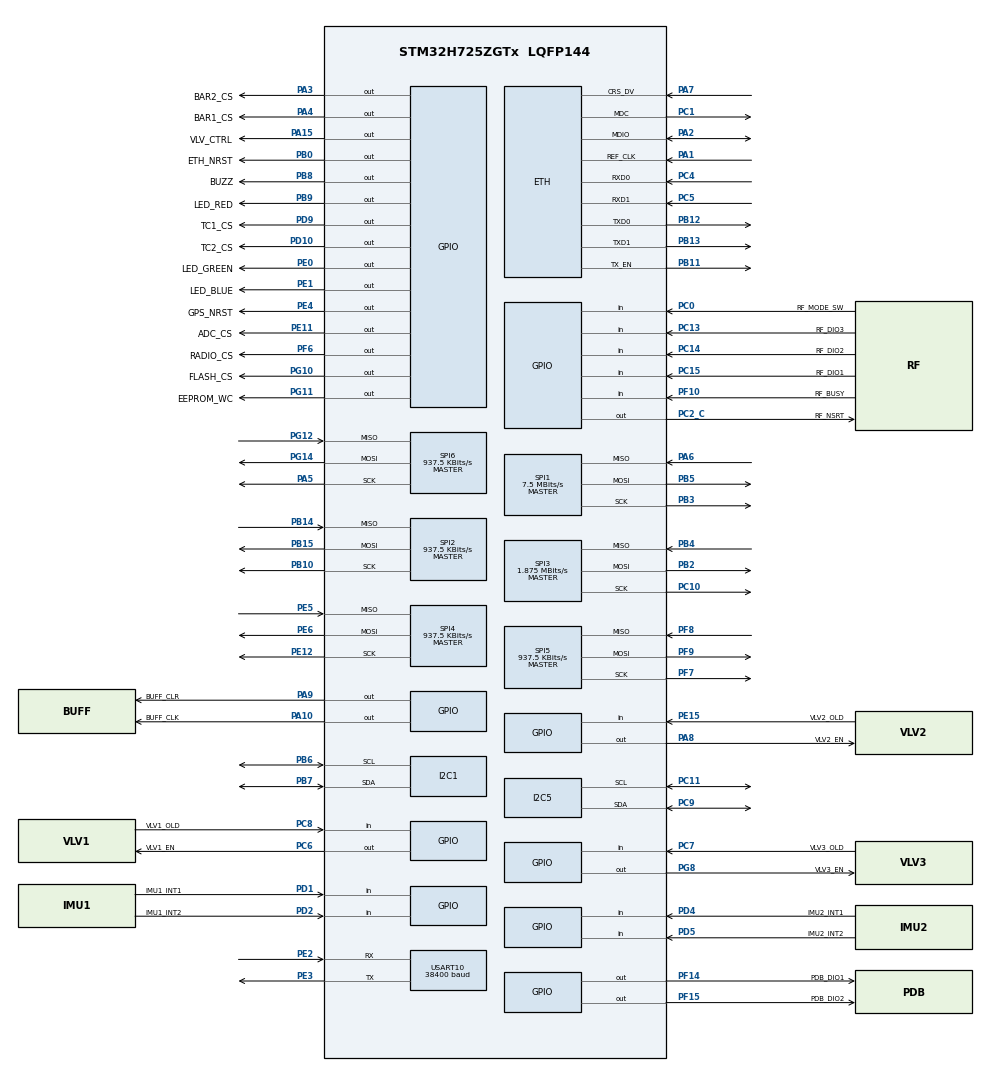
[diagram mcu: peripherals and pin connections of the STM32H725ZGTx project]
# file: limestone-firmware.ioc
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CORTEX_M7.AccessPermission-Cortex_Memory_Protection_Unit_Region0_Settings=MPU_REGION_NO_ACCESS
CORTEX_M7.AccessPermission-Cortex_Memory_Protection_Unit_Region1_Settings=MPU_REGION_FULL_ACCESS
CORTEX_M7.AccessPermission-Cortex_Memory_Protection_Unit_Region2_Settings=MPU_REGION_FULL_ACCESS
CORTEX_M7.AccessPermission_S-Cortex_Memory_Protection_Unit_Region1_Settings_S=MPU_REGION_FULL_ACCESS
CORTEX_M7.AccessPermission_S-Cortex_Memory_Protection_Unit_Region2_Settings_S=MPU_REGION_FULL_ACCESS
CORTEX_M7.AccessPermission_Spec=MPU_REGION_NO_ACCESS
CORTEX_M7.BaseAddress-Cortex_Memory_Protection_Unit_Region0_Settings=0x00000000
CORTEX_M7.BaseAddress-Cortex_Memory_Protection_Unit_Region1_Settings=0x30000200
CORTEX_M7.BaseAddress-Cortex_Memory_Protection_Unit_Region2_Settings=0x30000000
CORTEX_M7.BaseAddress_S-Cortex_Memory_Protection_Unit_Region1_Settings_S=0x30000200
CORTEX_M7.BaseAddress_S-Cortex_Memory_Protection_Unit_Region2_Settings_S=0x30000000
CORTEX_M7.CPU_DCache=Enabled
CORTEX_M7.CPU_ICache=Enabled
CORTEX_M7.DisableExec-Cortex_Memory_Protection_Unit_Region0_Settings=MPU_INSTRUCTION_ACCESS_DISABLE
CORTEX_M7.DisableExec-Cortex_Memory_Protection_Unit_Region1_Settings=MPU_INSTRUCTION_ACCESS_DISABLE
CORTEX_M7.DisableExec-Cortex_Memory_Protection_Unit_Region2_Settings=MPU_INSTRUCTION_ACCESS_DISABLE
CORTEX_M7.DisableExec_S-Cortex_Memory_Protection_Unit_Region1_Settings_S=MPU_INSTRUCTION_ACCESS_DISABLE
CORTEX_M7.DisableExec_S-Cortex_Memory_Protection_Unit_Region2_Settings_S=MPU_INSTRUCTION_ACCESS_DISABLE
CORTEX_M7.Enable-Cortex_Memory_Protection_Unit_Region0_Settings=MPU_REGION_ENABLE
CORTEX_M7.Enable-Cortex_Memory_Protection_Unit_Region1_Settings=MPU_REGION_ENABLE
CORTEX_M7.Enable-Cortex_Memory_Protection_Unit_Region2_Settings=MPU_REGION_ENABLE
CORTEX_M7.Enable_S-Cortex_Memory_Protection_Unit_Region1_Settings_S=MPU_REGION_ENABLE
CORTEX_M7.Enable_S-Cortex_Memory_Protection_Unit_Region2_Settings_S=MPU_REGION_ENABLE
CORTEX_M7.IsBufferable-Cortex_Memory_Protection_Unit_Region1_Settings=MPU_ACCESS_NOT_BUFFERABLE
CORTEX_M7.IsBufferable-Cortex_Memory_Protection_Unit_Region2_Settings=MPU_ACCESS_BUFFERABLE
CORTEX_M7.IsBufferable_S-Cortex_Memory_Protection_Unit_Region2_Settings_S=MPU_ACCESS_BUFFERABLE
CORTEX_M7.IsCacheable-Cortex_Memory_Protection_Unit_Region1_Settings=MPU_ACCESS_NOT_CACHEABLE
CORTEX_M7.IsShareable-Cortex_Memory_Protection_Unit_Region0_Settings=MPU_ACCESS_SHAREABLE
CORTEX_M7.IsShareable-Cortex_Memory_Protection_Unit_Region2_Settings=MPU_ACCESS_SHAREABLE
CORTEX_M7.IsShareable_S-Cortex_Memory_Protection_Unit_Region1_Settings_S=MPU_ACCESS_NOT_SHAREABLE
CORTEX_M7.IsShareable_S-Cortex_Memory_Protection_Unit_Region2_Settings_S=MPU_ACCESS_SHAREABLE
CORTEX_M7.MPU_Control=MPU_PRIVILEGED_DEFAULT
CORTEX_M7.Size-Cortex_Memory_Protection_Unit_Region0_Settings=MPU_REGION_SIZE_4GB
CORTEX_M7.Size-Cortex_Memory_Protection_Unit_Region1_Settings=MPU_REGION_SIZE_128KB
CORTEX_M7.Size-Cortex_Memory_Protection_Unit_Region2_Settings=MPU_REGION_SIZE_512B
CORTEX_M7.Size_S-Cortex_Memory_Protection_Unit_Region1_Settings_S=MPU_REGION_SIZE_32KB
CORTEX_M7.Size_S-Cortex_Memory_Protection_Unit_Region2_Settings_S=MPU_REGION_SIZE_512B
CORTEX_M7.SubRegionDisable-Cortex_Memory_Protection_Unit_Region0_Settings=0x87
CORTEX_M7.SubRegionDisable_S-Cortex_Memory_Protection_Unit_Region1_Settings_S=0x0
CORTEX_M7.TypeExtField-Cortex_Memory_Protection_Unit_Region1_Settings=MPU_TEX_LEVEL1
CORTEX_M7.TypeExtField_S-Cortex_Memory_Protection_Unit_Region1_Settings_S=MPU_TEX_LEVEL1
CORTEX_M7.default_mode_Activation=1
CRC.InputDataInversionMode=CRC_INPUTDATA_INVERSION_BYTE
CRC.OutputDataInversionMode=CRC_OUTPUTDATA_INVERSION_ENABLE
ETH.ETH_RX_DESC_CNT=8
ETH.ETH_TX_DESC_CNT=8
ETH.MediaInterface=HAL_ETH_RMII_MODE
ETH.RxBuffLen=1536
ETH.RxBufferAddress=0x30000200
ETH.TxDescAddress=0x30000100
FREERTOS.Tasks01=startTask,24,1024,StartAndMonitor,Default,NULL,Dynamic,NULL,NULL
FREERTOS.configCHECK_FOR_STACK_OVERFLOW=2
FREERTOS.configGENERATE_RUN_TIME_STATS=1
FREERTOS.configTOTAL_HEAP_SIZE=114688
FREERTOS.configUSE_NEWLIB_REENTRANT=1
I2C1.Timing=0x307075B1
I2C5.Timing=0x307075B1
LWIP.BSP.number=1
LWIP.DEFAULT_ACCEPTMBOX_SIZE=32
LWIP.DEFAULT_TCP_RECVMBOX_SIZE=64
LWIP.DEFAULT_UDP_RECVMBOX_SIZE=64
LWIP.ETHARP_DEBUG=LWIP_DBG_OFF
LWIP.ETH_RX_BUFFER_CNT=12
LWIP.IP_ADDRESS=000.000.000.000
LWIP.LWIP_DBG_MIN_LEVEL=LWIP_DBG_LEVEL_WARNING
LWIP.LWIP_DBG_TYPES_ON=LWIP_DBG_OFF
LWIP.LWIP_DHCP=0
LWIP.LWIP_NETCONN_SEM_PER_THREAD=0
LWIP.LWIP_PERF=1
LWIP.LWIP_RAM_HEAP_POINTER=0x30000200
LWIP.LWIP_SNTP=1
LWIP.LWIP_SO_RCVTIMEO=1
LWIP.LWIP_SO_SNDTIMEO=1
LWIP.LWIP_STATS=1
LWIP.LWIP_TCPIP_TIMEOUT=1
LWIP.LWIP_TCP_KEEPALIVE=1
LWIP.LWIP_TFTP=1
LWIP.MEMP_NUM_API_MSG=10
LWIP.MEMP_NUM_NETBUF=64
LWIP.MEMP_NUM_NETCONN=10
LWIP.MEMP_NUM_NETDB=4
LWIP.MEMP_NUM_SYS_TIMEOUT=16
LWIP.MEMP_NUM_TCPIP_MSG_INPKT=64
LWIP.MEMP_NUM_TCP_PCB=9
LWIP.MEMP_NUM_TCP_SEG=32
LWIP.MEMP_NUM_UDP_PCB=6
LWIP.MEM_SIZE=32232
LWIP.NETIF_DEBUG=LWIP_DBG_OFF
LWIP.NETMASK_ADDRESS=255.255.255.000
LWIP.PBUF_DEBUG=LWIP_DBG_OFF
LWIP.PBUF_POOL_BUFSIZE=1536
LWIP.PBUF_POOL_SIZE=64
LWIP.SO_REUSE=1
LWIP.SYS_DEBUG=LWIP_DBG_OFF
LWIP.TCPIP_MBOX_SIZE=64
LWIP.TCPIP_THREAD_STACKSIZE=6400
LWIP.TCP_CWND_DEBUG=LWIP_DBG_OFF
LWIP.TCP_DEBUG=LWIP_DBG_OFF
LWIP.TCP_FR_DEBUG=LWIP_DBG_OFF
LWIP.TCP_INPUT_DEBUG=LWIP_DBG_OFF
LWIP.TCP_MSS=1460
LWIP.TCP_OUTPUT_DEBUG=LWIP_DBG_OFF
LWIP.TCP_QLEN_DEBUG=LWIP_DBG_OFF
LWIP.TCP_RST_DEBUG=LWIP_DBG_OFF
LWIP.TCP_RTO_DEBUG=LWIP_DBG_OFF
LWIP.TCP_SND_BUF=5840
LWIP.TCP_SND_QUEUELEN=16
LWIP.TCP_WND_DEBUG=LWIP_DBG_OFF
LWIP.TIMERS_DEBUG=LWIP_DBG_OFF
LWIP.Version=v2.1.2_Cube
LWIP0.BSP.STBoard=false
LWIP0.BSP.api=BSP_COMPONENT_DRIVER
LWIP0.BSP.component=LAN8742
LWIP0.BSP.instance=LAN8742
LWIP0.BSP.name=Driver_PHY
LWIP0.BSP.semaphore=S_LAN8742
LWIP0.BSP.solution=LAN8742
Mcu.Family=STM32H7
Mcu.Name=STM32H725ZGTx
Mcu.Package=LQFP144
NVIC.ETH_IRQn=true\:5\:0\:true\:false\:true\:true\:true\:true\:true
NVIC.PriorityGroup=NVIC_PRIORITYGROUP_4
NVIC.TIM6_DAC_IRQn=true\:15\:0\:false\:false\:true\:false\:false\:true\:true
NVIC.TIM8_TRG_COM_TIM14_IRQn=true\:5\:0\:false\:false\:true\:true\:true\:true\:true
NVIC.TimeBase=TIM6_DAC_IRQn
NVIC.TimeBaseIP=TIM6
NVIC.USART10_IRQn=true\:5\:0\:false\:false\:true\:true\:true\:true\:true
PA1.GPIO_Speed=GPIO_SPEED_FREQ_VERY_HIGH
PA1.Mode=RMII
PA1.Signal=ETH_REF_CLK
PA10.GPIO_Label=BUFF_CLK
PA10.GPIO_Speed=GPIO_SPEED_FREQ_VERY_HIGH
PA10.Signal=GPIO_Output
PA13(JTMS/SWDIO).Mode=Serial_Wire
PA13(JTMS/SWDIO).Signal=DEBUG_JTMS-SWDIO
PA14(JTCK/SWCLK).Mode=Serial_Wire
PA14(JTCK/SWCLK).Signal=DEBUG_JTCK-SWCLK
PA15(JTDI).GPIO_Label=VLV_CTRL
PA15(JTDI).GPIO_PuPd=GPIO_NOPULL
PA15(JTDI).GPIO_Speed=GPIO_SPEED_FREQ_VERY_HIGH
PA15(JTDI).Signal=GPIO_Output
PA2.GPIO_Speed=GPIO_SPEED_FREQ_VERY_HIGH
PA2.Mode=RMII
PA2.Signal=ETH_MDIO
PA3.GPIO_Label=BAR2_CS
PA3.PinState=GPIO_PIN_SET
PA3.Signal=GPIO_Output
PA4.GPIO_Label=BAR1_CS
PA4.PinState=GPIO_PIN_SET
PA4.Signal=GPIO_Output
PA5.GPIO_Speed=GPIO_SPEED_FREQ_LOW
PA5.Mode=Full_Duplex_Master
PA5.Signal=SPI6_SCK
PA6.GPIO_Speed=GPIO_SPEED_FREQ_MEDIUM
PA6.Mode=Full_Duplex_Master
PA6.Signal=SPI1_MISO
PA7.GPIO_Speed=GPIO_SPEED_FREQ_VERY_HIGH
PA7.Mode=RMII
PA7.Signal=ETH_CRS_DV
PA8.GPIO_Label=VLV2_EN
PA8.Signal=GPIO_Output
PA9.GPIO_Label=BUFF_CLR
PA9.GPIO_Speed=GPIO_SPEED_FREQ_VERY_HIGH
PA9.Signal=GPIO_Output
PB0.GPIO_Label=ETH_NRST
PB0.PinState=GPIO_PIN_SET
PB0.Signal=GPIO_Output
PB10.GPIO_Speed=GPIO_SPEED_FREQ_LOW
PB10.Mode=Full_Duplex_Master
PB10.Signal=SPI2_SCK
PB11.GPIO_Speed=GPIO_SPEED_FREQ_VERY_HIGH
PB11.Mode=RMII
PB11.Signal=ETH_TX_EN
PB12.GPIO_Speed=GPIO_SPEED_FREQ_VERY_HIGH
PB12.Mode=RMII
PB12.Signal=ETH_TXD0
PB13.GPIO_Speed=GPIO_SPEED_FREQ_VERY_HIGH
PB13.Mode=RMII
PB13.Signal=ETH_TXD1
PB14.GPIO_Speed=GPIO_SPEED_FREQ_LOW
PB14.Mode=Full_Duplex_Master
PB14.Signal=SPI2_MISO
PB15.GPIO_Speed=GPIO_SPEED_FREQ_LOW
PB15.Mode=Full_Duplex_Master
PB15.Signal=SPI2_MOSI
PB2.GPIO_Speed=GPIO_SPEED_FREQ_LOW
PB2.Mode=Full_Duplex_Master
PB2.Signal=SPI3_MOSI
PB3(JTDO/TRACESWO).GPIO_Speed=GPIO_SPEED_FREQ_MEDIUM
PB3(JTDO/TRACESWO).Mode=Full_Duplex_Master
PB3(JTDO/TRACESWO).Signal=SPI1_SCK
PB4(NJTRST).GPIO_Speed=GPIO_SPEED_FREQ_LOW
PB4(NJTRST).Mode=Full_Duplex_Master
PB4(NJTRST).Signal=SPI3_MISO
PB5.GPIO_Speed=GPIO_SPEED_FREQ_MEDIUM
PB5.Mode=Full_Duplex_Master
PB5.Signal=SPI1_MOSI
PB6.Mode=I2C
PB6.Signal=I2C1_SCL
PB7.Mode=I2C
PB7.Signal=I2C1_SDA
PB8.GPIO_Label=BUZZ
PB8.Signal=GPIO_Output
PB9.GPIO_Label=LED_RED
PB9.Signal=GPIO_Output
PC0.GPIO_Label=RF_MODE_SW
PC0.Signal=GPIO_Input
PC1.GPIO_Speed=GPIO_SPEED_FREQ_VERY_HIGH
PC1.Mode=RMII
PC1.Signal=ETH_MDC
PC10.GPIO_Speed=GPIO_SPEED_FREQ_LOW
PC10.Mode=Full_Duplex_Master
PC10.Signal=SPI3_SCK
PC11.Mode=I2C
PC11.Signal=I2C5_SCL
PC13.GPIO_Label=RF_DIO3
PC13.Signal=GPIO_Input
PC14-OSC32_IN.GPIO_Label=RF_DIO2
PC14-OSC32_IN.Signal=GPIO_Input
PC15-OSC32_OUT.GPIO_Label=RF_DIO1
PC15-OSC32_OUT.Signal=GPIO_Input
PC2_C.GPIO_Label=RF_NSRT
PC2_C.PinState=GPIO_PIN_SET
PC2_C.Signal=GPIO_Output
PC4.GPIO_Speed=GPIO_SPEED_FREQ_VERY_HIGH
PC4.Mode=RMII
PC4.Signal=ETH_RXD0
PC5.GPIO_Speed=GPIO_SPEED_FREQ_VERY_HIGH
PC5.Mode=RMII
PC5.Signal=ETH_RXD1
PC6.GPIO_Label=VLV1_EN
PC6.Signal=GPIO_Output
PC7.GPIO_Label=VLV3_OLD
PC7.Signal=GPIO_Input
PC8.GPIO_Label=VLV1_OLD
PC8.Signal=GPIO_Input
PC9.Mode=I2C
PC9.Signal=I2C5_SDA
PD1.GPIO_Label=IMU1_INT1
PD1.Signal=GPIO_Input
PD10.GPIO_Label=TC2_CS
PD10.PinState=GPIO_PIN_SET
PD10.Signal=GPIO_Output
PD2.GPIO_Label=IMU1_INT2
PD2.Signal=GPIO_Input
PD4.GPIO_Label=IMU2_INT1
PD4.Signal=GPIO_Input
PD5.GPIO_Label=IMU2_INT2
PD5.Signal=GPIO_Input
PD9.GPIO_Label=TC1_CS
PD9.PinState=GPIO_PIN_SET
PD9.Signal=GPIO_Output
PE0.GPIO_Label=LED_GREEN
PE0.Signal=GPIO_Output
PE1.GPIO_Label=LED_BLUE
PE1.Signal=GPIO_Output
PE11.GPIO_Label=ADC_CS
PE11.PinState=GPIO_PIN_SET
PE11.Signal=GPIO_Output
PE12.Mode=Full_Duplex_Master
PE12.Signal=SPI4_SCK
PE15.GPIO_Label=VLV2_OLD
PE15.Signal=GPIO_Input
PE2.Mode=Asynchronous
PE2.Signal=USART10_RX
PE3.Mode=Asynchronous
PE3.Signal=USART10_TX
PE4.GPIO_Label=GPS_NRST
PE4.PinState=GPIO_PIN_SET
PE4.Signal=GPIO_Output
PE5.GPIO_Speed=GPIO_SPEED_FREQ_LOW
PE5.Mode=Full_Duplex_Master
PE5.Signal=SPI4_MISO
PE6.GPIO_Speed=GPIO_SPEED_FREQ_LOW
PE6.Mode=Full_Duplex_Master
PE6.Signal=SPI4_MOSI
PF10.GPIO_Label=RF_BUSY
PF10.Signal=GPIO_Input
PF14.GPIO_Label=PDB_DIO1
PF14.Signal=GPIO_Output
PF15.GPIO_Label=PDB_DIO2
PF15.Signal=GPIO_Output
PF6.GPIO_Label=RADIO_CS
PF6.PinState=GPIO_PIN_SET
PF6.Signal=GPIO_Output
PF7.Mode=Full_Duplex_Master
PF7.Signal=SPI5_SCK
PF8.Mode=Full_Duplex_Master
PF8.Signal=SPI5_MISO
PF9.Mode=Full_Duplex_Master
PF9.Signal=SPI5_MOSI
PG10.GPIO_Label=FLASH_CS
PG10.PinState=GPIO_PIN_SET
PG10.Signal=GPIO_Output
PG11.GPIO_Label=EEPROM_WC
PG11.PinState=GPIO_PIN_SET
PG11.Signal=GPIO_Output
PG12.Mode=Full_Duplex_Master
PG12.Signal=SPI6_MISO
PG14.Mode=Full_Duplex_Master
PG14.Signal=SPI6_MOSI
PG8.GPIO_Label=VLV3_EN
PG8.Signal=GPIO_Output
PH0-OSC_IN.Mode=HSE-External-Oscillator
PH0-OSC_IN.Signal=RCC_OSC_IN
PH1-OSC_OUT.Mode=HSE-External-Oscillator
PH1-OSC_OUT.Signal=RCC_OSC_OUT
ProjectManager.HeapSize=0x200
ProjectManager.StackSize=0x400
ProjectManager.TargetToolchain=STM32CubeIDE
RCC.ADCFreq_Value=387000000
RCC.APB1Freq_Value=120000000
RCC.APB2Freq_Value=120000000
RCC.APB3Freq_Value=120000000
RCC.APB4Freq_Value=120000000
RCC.CortexFreq_Value=480000000
RCC.D1PPRE=RCC_APB3_DIV2
RCC.D2PPRE1=RCC_APB1_DIV2
RCC.D2PPRE2=RCC_APB2_DIV2
RCC.D3PPRE=RCC_APB4_DIV2
RCC.DIVM1=3
RCC.DIVM2=8
RCC.DIVM3=8
RCC.DIVN1=30
RCC.DIVP1=1
RCC.HCLKFreq_Value=240000000
RCC.HPRE=RCC_HCLK_DIV2
RCC.HSE_VALUE=48000000
RCC.PLLFRACN=0
RCC.PLLSourceVirtual=RCC_PLLSOURCE_HSE
RCC.RCC_RTC_Clock_Source_FROM_HSE=RCC_RTCCLKSOURCE_HSE_DIV60
RCC.RTCClockSelection=RCC_RTCCLKSOURCE_HSE_DIV60
RCC.SYSCLKFreq_VALUE=480000000
RCC.SYSCLKSource=RCC_SYSCLKSOURCE_PLLCLK
RCC.SupplySource=PWR_LDO_SUPPLY
RCC.USBFreq_Value=240000000
RTC.Format=RTC_FORMAT_BIN
RTC.SynchPrediv=6249
SPI1.BaudRatePrescaler=SPI_BAUDRATEPRESCALER_32
SPI1.CalculateBaudRate=7.5 MBits/s
SPI1.DataSize=SPI_DATASIZE_8BIT
SPI1.Direction=SPI_DIRECTION_2LINES
SPI1.Mode=SPI_MODE_MASTER
SPI1.VirtualType=VM_MASTER
SPI2.BaudRatePrescaler=SPI_BAUDRATEPRESCALER_256
SPI2.CLKPhase=SPI_PHASE_2EDGE
SPI2.CalculateBaudRate=937.5 KBits/s
SPI2.DataSize=SPI_DATASIZE_8BIT
SPI2.Direction=SPI_DIRECTION_2LINES
SPI2.Mode=SPI_MODE_MASTER
SPI2.VirtualType=VM_MASTER
SPI3.BaudRatePrescaler=SPI_BAUDRATEPRESCALER_128
SPI3.CalculateBaudRate=1.875 MBits/s
SPI3.DataSize=SPI_DATASIZE_8BIT
SPI3.Direction=SPI_DIRECTION_2LINES
SPI3.Mode=SPI_MODE_MASTER
SPI3.VirtualType=VM_MASTER
SPI4.BaudRatePrescaler=SPI_BAUDRATEPRESCALER_128
SPI4.CLKPhase=SPI_PHASE_2EDGE
SPI4.CLKPolarity=SPI_POLARITY_HIGH
SPI4.CalculateBaudRate=937.5 KBits/s
SPI4.DataSize=SPI_DATASIZE_8BIT
SPI4.Direction=SPI_DIRECTION_2LINES
SPI4.Mode=SPI_MODE_MASTER
SPI4.VirtualType=VM_MASTER
SPI5.BaudRatePrescaler=SPI_BAUDRATEPRESCALER_128
SPI5.CalculateBaudRate=937.5 KBits/s
SPI5.DataSize=SPI_DATASIZE_8BIT
SPI5.Direction=SPI_DIRECTION_2LINES
SPI5.Mode=SPI_MODE_MASTER
SPI5.VirtualType=VM_MASTER
SPI6.BaudRatePrescaler=SPI_BAUDRATEPRESCALER_128
SPI6.CalculateBaudRate=937.5 KBits/s
SPI6.DataSize=SPI_DATASIZE_8BIT
SPI6.Direction=SPI_DIRECTION_2LINES
SPI6.Mode=SPI_MODE_MASTER
SPI6.VirtualType=VM_MASTER
USART10.BaudRate=38400
USART10.FIFOMode=FIFOMODE_ENABLE
USART10.VirtualMode-Asynchronous=VM_ASYNC
VP_CRC_VS_CRC.Mode=CRC_Activate
VP_FREERTOS_VS_CMSIS_V2.Mode=CMSIS_V2
VP_LWIP_VS_Enabled.Mode=Enabled
VP_MEMORYMAP_VS_MEMORYMAP.Mode=CurAppReg
VP_RTC_VS_RTC_Activate.Mode=RTC_Enabled
VP_RTC_VS_RTC_Calendar.Mode=RTC_Calendar
VP_SYS_VS_tim6.Mode=TIM6
VP_TIM14_VS_ClockSourceINT.Mode=Enable_Timer
board=custom

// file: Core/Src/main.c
/* USER CODE BEGIN Header */
/**
  ******************************************************************************
  * @file           : main.c
  * @brief          : Main program body
  ******************************************************************************
  * @attention
  *
  * Copyright (c) 2024 STMicroelectronics.
  * All rights reserved.
  *
  * This software is licensed under terms that can be found in the LICENSE file
  * in the root directory of this software component.
  * If no LICENSE file comes with this software, it is provided AS-IS.
  *
  ******************************************************************************
  */
/* USER CODE END Header */
#include "main.h"
#include "cmsis_os.h"
#include "lwip.h"

/* USER CODE BEGIN Includes */
#include "api.h"
#include "server.h"
#include "math.h"
#include "semphr.h"
#include "time-sync.h"
#include "logging.h"
#include "telemetry.h"
#include "network-processing.h"
#include "MS5611.h"
#include "ADS1120.h"
#include "MAX11128.h"
#include "LSM6DSO32XTR.h"
#include "messages.h"
#include "M24256E.h"
#include "utils.h"
#include "VLVs.h"
#include "eeprom-config.h"
#include "log_errors.h"
#include "udptelemetry.h"
#include "NEO-M92-00B.h"
#include "flight-autosequence.h"
#include "radio-telem.h"
//#include "lwip/netif.h"
/* USER CODE END Includes */

/* USER CODE BEGIN PD */
// Fuck stm32 and their support for half of something and not the rest
// These make malloc() and free() thread safe
void __malloc_lock(struct _reent *r) {
    if(xTaskGetSchedulerState() != taskSCHEDULER_NOT_STARTED) {
        vTaskSuspendAll();
    }
}

void __malloc_unlock(struct _reent *r) {
    if(xTaskGetSchedulerState() != taskSCHEDULER_NOT_STARTED) {
        (void)xTaskResumeAll();
    }
}
/* USER CODE END PD */

CRC_HandleTypeDef hcrc;

I2C_HandleTypeDef hi2c1;
I2C_HandleTypeDef hi2c5;

RTC_HandleTypeDef hrtc;

SPI_HandleTypeDef hspi1;
SPI_HandleTypeDef hspi2;
SPI_HandleTypeDef hspi3;
SPI_HandleTypeDef hspi4;
SPI_HandleTypeDef hspi5;
SPI_HandleTypeDef hspi6;

TIM_HandleTypeDef htim14;

UART_HandleTypeDef huart10;

/* Definitions for startTask */
osThreadId_t startTaskHandle;
const osThreadAttr_t startTask_attributes = {
  .name = "startTask",
  .stack_size = 1024 * 4,
  .priority = (osPriority_t) osPriorityNormal,
};
/* USER CODE BEGIN PV */
extern struct netif gnetif;

ip4_addr_t fc_addr;

inittimers_t timers = {0};
SemaphoreHandle_t timer_mutex = NULL;

EEPROM_conf_t loaded_config = {0};
PT_t PT1_h = {0.5f, 5000.0f, 4.5f}; // Default
PT_t PT2_h = {0.5f, 5000.0f, 4.5f};
PT_t PT3_h = {0.5f, 5000.0f, 4.5f};
PT_t PT4_h = {0.5f, 5000.0f, 4.5f};
PT_t PT5_h = {0.5f, 5000.0f, 4.5f};

Sensors_t sensors_h = {0};

SX1280_Hal_t radio_config;

osThreadId_t telemetryTaskHandle;
const osThreadAttr_t telemetry_task_attr = {
  .name = "telemetryTask",
  .stack_size = 512 * 4,
  .priority = (osPriority_t) osPriorityNormal,
};

osThreadId_t telemetryUDPTaskHandle;
const osThreadAttr_t telemetry_udp_task_attr = {
  .name = "telemetryUDPTask",
  .stack_size = 576 * 4,
  .priority = (osPriority_t) osPriorityNormal,
};

osThreadId_t packetTaskHandle;
const osThreadAttr_t packet_task_attr = {
  .name = "packetTask",
  .stack_size = 512 * 4,
  .priority = (osPriority_t) osPriorityNormal,
};

osThreadId_t flashClearTaskHandle;
const osThreadAttr_t flash_clear_task_attr = {
  .name = "flashCTask",
  .stack_size = 1024 * 4,
  .priority = (osPriority_t) osPriorityNormal,
};

osThreadId_t autosequenceTaskHandle;
const osThreadAttr_t autosequence_task_attr = {
  .name = "autosequence",
  .stack_size = AUTOSEQUENCE_TASK_STACK,
  .priority = (osPriority_t) osPriorityNormal,
};

osThreadId_t radioTaskHandle;
const osThreadAttr_t radio_task_attr = {
  .name = "radio",
  .stack_size = 512 * 4,
  .priority = (osPriority_t) osPriorityNormal,
};
/* USER CODE END PV */

void SystemClock_Config(void);
static void MPU_Config(void);
static void MX_GPIO_Init(void);
static void MX_I2C1_Init(void);
static void MX_I2C5_Init(void);
static void MX_SPI4_Init(void);
static void MX_SPI5_Init(void);
static void MX_USART10_UART_Init(void);
static void MX_RTC_Init(void);
static void MX_SPI1_Init(void);
static void MX_SPI2_Init(void);
static void MX_SPI6_Init(void);
static void MX_CRC_Init(void);
static void MX_SPI3_Init(void);
static void MX_TIM14_Init(void);
void StartAndMonitor(void *argument);

/* USER CODE BEGIN 0 */
uint64_t getTimestamp() {
	return HAL_GetTick();
}

void toggleBuzzer(TimerHandle_t xTimer) {
	HAL_GPIO_TogglePin(BUZZ_GPIO_Port, BUZZ_Pin);
}

void toggleLEDPins(TimerHandle_t xTimer) {
	HAL_GPIO_TogglePin(LED_RED_GPIO_Port, LED_RED_Pin);
	HAL_GPIO_TogglePin(LED_GREEN_GPIO_Port, LED_GREEN_Pin);
	HAL_GPIO_TogglePin(LED_BLUE_GPIO_Port, LED_BLUE_Pin);
}

void buzzerOff() {
	HAL_GPIO_WritePin(BUZZ_GPIO_Port, BUZZ_Pin, 0);
}

void buzzerOn() {
	HAL_GPIO_WritePin(BUZZ_GPIO_Port, BUZZ_Pin, 1);
}

void stopLEDtimer() {
	if(xSemaphoreTake(timer_mutex, 1) == pdPASS) {
		if(timers.ledTimer) {
			xTimerStop(timers.ledTimer, 0);
			HAL_GPIO_WritePin(LED_RED_GPIO_Port, LED_RED_Pin, 1);
			HAL_GPIO_WritePin(LED_GREEN_GPIO_Port, LED_GREEN_Pin, 1);
			HAL_GPIO_WritePin(LED_BLUE_GPIO_Port, LED_BLUE_Pin, 1);
		}
		xSemaphoreGive(timer_mutex);
	}
}

void start_led_timer(TickType_t delay, uint32_t reload, uint8_t force) {
	if(xSemaphoreTake(timer_mutex, 0) == pdPASS) {
		if(timers.ledTimer) {
			if(force || xTimerIsTimerActive(timers.ledTimer) != pdPASS) {
				vTimerSetTimerID(timers.ledTimer, (void *)reload);
				xTimerChangePeriod(timers.ledTimer, delay, 0);
			}
		}
		xSemaphoreGive(timer_mutex);
	}
}

void start_buzz_timer(TickType_t delay, uint32_t reload, uint8_t force, uint8_t startMode) {
	if(xSemaphoreTake(timer_mutex, 0) == pdPASS) {
		if(timers.buzzTimer) {
			if(force || xTimerIsTimerActive(timers.buzzTimer) != pdPASS) {
				HAL_GPIO_WritePin(BUZZ_GPIO_Port, BUZZ_Pin, startMode);
				vTimerSetTimerID(timers.buzzTimer, (void *)reload);
				xTimerChangePeriod(timers.buzzTimer, delay, 0);
			}
		}
		xSemaphoreGive(timer_mutex);
	}
}

void BuzzTimer(TimerHandle_t xTimer) {
    uint32_t toggleCount = (uint32_t) pvTimerGetTimerID(xTimer);

    HAL_GPIO_TogglePin(BUZZ_GPIO_Port, BUZZ_Pin);

    if(toggleCount == 0) {
    	HAL_GPIO_WritePin(BUZZ_GPIO_Port, BUZZ_Pin, 0);
        xTimerStop(xTimer, 0);
        return;
    }

    toggleCount--;

    vTimerSetTimerID(xTimer, (void *)toggleCount);
}

void LEDTimer(TimerHandle_t xTimer) {
    uint32_t toggleCount = (uint32_t) pvTimerGetTimerID(xTimer);

	HAL_GPIO_TogglePin(LED_RED_GPIO_Port, LED_RED_Pin);
	HAL_GPIO_TogglePin(LED_GREEN_GPIO_Port, LED_GREEN_Pin);
	HAL_GPIO_TogglePin(LED_BLUE_GPIO_Port, LED_BLUE_Pin);

    if(toggleCount == 0) {
		HAL_GPIO_WritePin(LED_RED_GPIO_Port, LED_RED_Pin, 1);
		HAL_GPIO_WritePin(LED_GREEN_GPIO_Port, LED_GREEN_Pin, 1);
		HAL_GPIO_WritePin(LED_BLUE_GPIO_Port, LED_BLUE_Pin, 1);
        xTimerStop(xTimer, 0);
        return;
    }

    toggleCount--;

    vTimerSetTimerID(xTimer, (void *)toggleCount);
}

static void Enable_GPIO_Clock(GPIO_TypeDef *port) {
    if (port == GPIOA) __HAL_RCC_GPIOA_CLK_ENABLE();
    else if (port == GPIOB) __HAL_RCC_GPIOB_CLK_ENABLE();
    else if (port == GPIOC) __HAL_RCC_GPIOC_CLK_ENABLE();
    else if (port == GPIOD) __HAL_RCC_GPIOD_CLK_ENABLE();
    else if (port == GPIOE) __HAL_RCC_GPIOE_CLK_ENABLE();
    else if (port == GPIOF) __HAL_RCC_GPIOF_CLK_ENABLE();
    else if (port == GPIOG) __HAL_RCC_GPIOG_CLK_ENABLE();
    else if (port == GPIOH) __HAL_RCC_GPIOH_CLK_ENABLE();
#ifdef GPIOI
    else if (port == GPIOI) __HAL_RCC_GPIOI_CLK_ENABLE();
#endif
    else if (port == GPIOJ) __HAL_RCC_GPIOJ_CLK_ENABLE();
    else if (port == GPIOK) __HAL_RCC_GPIOK_CLK_ENABLE();
}

void clear_i2c_bus(GPIO_TypeDef * scl_port, uint16_t scl_pin, GPIO_TypeDef * sda_port, uint16_t sda_pin) {
	Enable_GPIO_Clock(scl_port);
	Enable_GPIO_Clock(sda_port);

    GPIO_InitTypeDef GPIO_InitStruct = {0};

    GPIO_InitStruct.Pin = scl_pin;
    GPIO_InitStruct.Mode = GPIO_MODE_OUTPUT_OD;
    GPIO_InitStruct.Pull = GPIO_NOPULL;
    GPIO_InitStruct.Speed = GPIO_SPEED_FREQ_HIGH;
    HAL_GPIO_Init(scl_port, &GPIO_InitStruct);

    GPIO_InitStruct.Pin = sda_pin;
    GPIO_InitStruct.Mode = GPIO_MODE_OUTPUT_OD;
    GPIO_InitStruct.Pull = GPIO_NOPULL;
    GPIO_InitStruct.Speed = GPIO_SPEED_FREQ_HIGH;
    HAL_GPIO_Init(sda_port, &GPIO_InitStruct);

    HAL_GPIO_WritePin(sda_port, sda_pin, GPIO_PIN_SET);

    for (uint8_t i = 0; i < 9; i++) {
        if (HAL_GPIO_ReadPin(sda_port, sda_pin) == GPIO_PIN_SET) {
            break;
        }

        HAL_GPIO_WritePin(scl_port, scl_pin, GPIO_PIN_RESET);
        HAL_Delay(1);

        HAL_GPIO_WritePin(scl_port, scl_pin, GPIO_PIN_SET);
        HAL_Delay(1);
    }

    HAL_GPIO_WritePin(scl_port, scl_pin, GPIO_PIN_SET);
    HAL_Delay(1);
    HAL_GPIO_WritePin(sda_port, sda_pin, GPIO_PIN_RESET);
    HAL_Delay(1);
    HAL_GPIO_WritePin(sda_port, sda_pin, GPIO_PIN_SET);
    HAL_Delay(1);

    HAL_GPIO_DeInit(sda_port, sda_pin);
    HAL_GPIO_DeInit(scl_port, scl_pin);
}
/* USER CODE END 0 */

int main(void)
{

  /* MPU Configuration--------------------------------------------------------*/
  MPU_Config();

  /* Enable the CPU Cache */

  /* Enable I-Cache---------------------------------------------------------*/
  SCB_EnableICache();

  /* Enable D-Cache---------------------------------------------------------*/
  SCB_EnableDCache();

  /* MCU Configuration--------------------------------------------------------*/

  /* Reset of all peripherals, Initializes the Flash interface and the Systick. */
  HAL_Init();

  /* Configure the system clock */
  SystemClock_Config();

  /* USER CODE BEGIN SysInit */
  // RTC init code - enable backup domain access because we're using HSE / 60 as RTC clock source
  HAL_PWR_EnableBkUpAccess();
  // Force reset RTC registers in case something got corrupted
  __HAL_RCC_BACKUPRESET_FORCE();
  __HAL_RCC_BACKUPRESET_RELEASE();

  clear_i2c_bus(GPIOB, GPIO_PIN_6, GPIOB, GPIO_PIN_7);
  clear_i2c_bus(GPIOC, GPIO_PIN_11, GPIOC, GPIO_PIN_9);
  /* USER CODE END SysInit */

  /* Initialize all configured peripherals */
  MX_GPIO_Init();
  MX_I2C1_Init();
  MX_I2C5_Init();
  MX_SPI4_Init();
  MX_SPI5_Init();
  MX_USART10_UART_Init();
  MX_RTC_Init();
  MX_SPI1_Init();
  MX_SPI2_Init();
  MX_SPI6_Init();
  MX_CRC_Init();
  MX_SPI3_Init();
  MX_TIM14_Init();

  /* Init scheduler */
  osKernelInitialize();

  /* USER CODE BEGIN RTOS_MUTEX */
  /* add mutexes, ... */
  timer_mutex = xSemaphoreCreateMutex();
  timers.buzzTimer = xTimerCreate("buzz", 1000, pdTRUE, (void *)0, BuzzTimer);
  timers.ledTimer = xTimerCreate("led", 1000, pdTRUE, (void *)0, LEDTimer);

  timesync_setup(&hrtc);
  if(logging_setup()) {
	  for(;;) {}
  }
  if(telemetry_setup()) {
	  for(;;) {}
  }
  setup_autosequence();
  /* USER CODE END RTOS_MUTEX */

  /* USER CODE BEGIN RTOS_QUEUES */
  /* add queues, ... */

  // This next section is considered the "critical" portion of initialization. This portion has no access to logging and therefore needs to communicate status other ways. The section ends on the return of the MX_LWIP_Init function
  // The end of this section is marked by a UDP message and/or the on-board LED becoming solid and/or a short buzzer beep

  // Load EEPROM config
  loaded_config.pt1 = &PT1_h;
  loaded_config.pt2 = &PT2_h;
  loaded_config.pt3 = &PT3_h;
  loaded_config.pt4 = &PT4_h;
  loaded_config.pt5 = &PT5_h;
  if(setup_eeprom(&hi2c1, EEPROM_WC_GPIO_Port, EEPROM_WC_Pin)) {
#ifdef EEPROM_OVERRIDE
	  load_eeprom_defaults(&loaded_config);
	  log_message(STAT_EEPROM_DEFAULT_LOADED, -1);
#else
	  switch(load_eeprom_config(&loaded_config)) {
	  	  case -1: {
	  		  // eeprom load error, defaults loaded
	  		  load_eeprom_defaults(&loaded_config);
	  		  log_message(ERR_EEPROM_LOAD_COMM_ERR, -1);
	  		  start_buzz_timer(500, UINT32_MAX, 1, 0);
	  		  break;
	  	  }
	  	  case -2: {
	  		  // eeprom tc gain value error
	  		  log_message(ERR_EEPROM_LOAD_TC_ERR, -1);
	  		  loaded_config.tc1_gain = FC_EEPROM_TC_GAIN_DEFAULT;
	  		  loaded_config.tc2_gain = FC_EEPROM_TC_GAIN_DEFAULT;
	  		  loaded_config.tc3_gain = FC_EEPROM_TC_GAIN_DEFAULT;
	  		  start_buzz_timer(500, UINT32_MAX, 1, 0);
	  		  break;
	  	  }
	  	  case -3: {
	  		  // eeprom valve conf error
	  		  log_message(ERR_EEPROM_LOAD_VLV_ERR, -1);
	  		  loaded_config.vlv1_en = FC_EEPROM_VLV_EN_DEFAULT;
	  		  loaded_config.vlv1_v = FC_EEPROM_VLV_VOL_DEFAULT;
	  		  loaded_config.vlv2_en = FC_EEPROM_VLV_EN_DEFAULT;
	  		  loaded_config.vlv2_v = FC_EEPROM_VLV_VOL_DEFAULT;
	  		  loaded_config.vlv3_en = FC_EEPROM_VLV_EN_DEFAULT;
	  		  loaded_config.vlv3_v = FC_EEPROM_VLV_VOL_DEFAULT;
	  		  start_buzz_timer(500, UINT32_MAX, 1, 0);
	  		  break;
	  	  }
	  	  case -4: {
	  		  // autosequence channel conf error
	  		  log_message(FC_ERR_EEPROM_LOAD_AUTOS_ERR, -1);
	  		  loaded_config.ox_mpv_index = FC_EEPROM_OX_MPV_DEFAULT;
	  		  loaded_config.fuel_mpv_index = FC_EEPROM_FUEL_MPV_DEFAULT;
	  		  loaded_config.pilot_para_index = FC_EEPROM_PILOT_DEFAULT;
	  		  loaded_config.drogue_para_index = FC_EEPROM_DROGUE_DEFAULT;
	  		  loaded_config.main_para_index = FC_EEPROM_MAIN_DEFAULT;
	  		  loaded_config.fuel_iso_index = FC_EEPROM_FUEL_ISO_DEFAULT;
	  		  loaded_config.ox_iso_index = FC_EEPROM_OX_ISO_DEFAULT;
	  		  start_buzz_timer(500, UINT32_MAX, 1, 0);
	  		  break;
	  	  }
	  	  default: {
	  		  // eeprom conf loaded
	  		  log_message(STAT_EEPROM_LOADED, -1);
	  		  break;
	  	  }
	  }
#endif
  }
  else {
	  // eeprom init error, defaults loaded
	  load_eeprom_defaults(&loaded_config);
	  log_message(ERR_EEPROM_INIT, -1);
	  start_buzz_timer(500, UINT32_MAX, 1, 0);
  }
  char channel_assign[] = FC_STAT_AUTOS_VALVES;
  channel_assign[46] = loaded_config.ox_mpv_index + 1 + '0';
  channel_assign[59] = loaded_config.fuel_mpv_index + 1 + '0';
  channel_assign[69] = loaded_config.pilot_para_index + 1 + '0';
  channel_assign[80] = loaded_config.drogue_para_index + 1 + '0';
  channel_assign[89] = loaded_config.main_para_index + 1 + '0';
  channel_assign[102] = loaded_config.fuel_iso_index + 1 + '0';
  channel_assign[113] = loaded_config.ox_iso_index + 1 + '0';
  log_message(channel_assign, -1);
  fc_addr = loaded_config.flightcomputerIP;
  log_message(STAT_VERSION_INFO, -1);

  // Init flash
  if(init_flash_logging(&hspi1, FLASH_CS_GPIO_Port, FLASH_CS_Pin)) {
	  start_led_timer(500, UINT32_MAX, 1);
  }

  init_radio(get_radio_state(0) == 1);
  /* USER CODE END RTOS_QUEUES */

  /* Create the thread(s) */
  /* creation of startTask */
  startTaskHandle = osThreadNew(StartAndMonitor, NULL, &startTask_attributes);

  /* USER CODE BEGIN RTOS_THREADS */
  /* add threads, ... */
  flashClearTaskHandle = osThreadNew(FlashClearTask, NULL, &flash_clear_task_attr);
  /* USER CODE END RTOS_THREADS */

  /* Start scheduler */
  osKernelStart();

  /* We should never get here as control is now taken by the scheduler */

  /* Infinite loop */
  while (1)
  {

  }
}

void SystemClock_Config(void)
{
  RCC_OscInitTypeDef RCC_OscInitStruct = {0};
  RCC_ClkInitTypeDef RCC_ClkInitStruct = {0};

  /** Supply configuration update enable
  */
  HAL_PWREx_ConfigSupply(PWR_LDO_SUPPLY);

  /** Configure the main internal regulator output voltage
  */
  __HAL_PWR_VOLTAGESCALING_CONFIG(PWR_REGULATOR_VOLTAGE_SCALE0);

  while(!__HAL_PWR_GET_FLAG(PWR_FLAG_VOSRDY)) {}

  /** Initializes the RCC Oscillators according to the specified parameters
  * in the RCC_OscInitTypeDef structure.
  */
  RCC_OscInitStruct.OscillatorType = RCC_OSCILLATORTYPE_HSE;
  RCC_OscInitStruct.HSEState = RCC_HSE_ON;
  RCC_OscInitStruct.PLL.PLLState = RCC_PLL_ON;
  RCC_OscInitStruct.PLL.PLLSource = RCC_PLLSOURCE_HSE;
  RCC_OscInitStruct.PLL.PLLM = 3;
  RCC_OscInitStruct.PLL.PLLN = 30;
  RCC_OscInitStruct.PLL.PLLP = 1;
  RCC_OscInitStruct.PLL.PLLQ = 2;
  RCC_OscInitStruct.PLL.PLLR = 2;
  RCC_OscInitStruct.PLL.PLLRGE = RCC_PLL1VCIRANGE_3;
  RCC_OscInitStruct.PLL.PLLVCOSEL = RCC_PLL1VCOWIDE;
  RCC_OscInitStruct.PLL.PLLFRACN = 0;
  if (HAL_RCC_OscConfig(&RCC_OscInitStruct) != HAL_OK)
  {
    Error_Handler();
  }

  /** Initializes the CPU, AHB and APB buses clocks
  */
  RCC_ClkInitStruct.ClockType = RCC_CLOCKTYPE_HCLK|RCC_CLOCKTYPE_SYSCLK
                              |RCC_CLOCKTYPE_PCLK1|RCC_CLOCKTYPE_PCLK2
                              |RCC_CLOCKTYPE_D3PCLK1|RCC_CLOCKTYPE_D1PCLK1;
  RCC_ClkInitStruct.SYSCLKSource = RCC_SYSCLKSOURCE_PLLCLK;
  RCC_ClkInitStruct.SYSCLKDivider = RCC_SYSCLK_DIV1;
  RCC_ClkInitStruct.AHBCLKDivider = RCC_HCLK_DIV2;
  RCC_ClkInitStruct.APB3CLKDivider = RCC_APB3_DIV2;
  RCC_ClkInitStruct.APB1CLKDivider = RCC_APB1_DIV2;
  RCC_ClkInitStruct.APB2CLKDivider = RCC_APB2_DIV2;
  RCC_ClkInitStruct.APB4CLKDivider = RCC_APB4_DIV2;

  if (HAL_RCC_ClockConfig(&RCC_ClkInitStruct, FLASH_LATENCY_3) != HAL_OK)
  {
    Error_Handler();
  }
}

static void MX_CRC_Init(void)
{

  hcrc.Instance = CRC;
  hcrc.Init.DefaultPolynomialUse = DEFAULT_POLYNOMIAL_ENABLE;
  hcrc.Init.DefaultInitValueUse = DEFAULT_INIT_VALUE_ENABLE;
  hcrc.Init.InputDataInversionMode = CRC_INPUTDATA_INVERSION_BYTE;
  hcrc.Init.OutputDataInversionMode = CRC_OUTPUTDATA_INVERSION_ENABLE;
  hcrc.InputDataFormat = CRC_INPUTDATA_FORMAT_BYTES;
  if (HAL_CRC_Init(&hcrc) != HAL_OK)
  {
    Error_Handler();
  }

}

static void MX_I2C1_Init(void)
{

  hi2c1.Instance = I2C1;
  hi2c1.Init.Timing = 0x307075B1;
  hi2c1.Init.OwnAddress1 = 0;
  hi2c1.Init.AddressingMode = I2C_ADDRESSINGMODE_7BIT;
  hi2c1.Init.DualAddressMode = I2C_DUALADDRESS_DISABLE;
  hi2c1.Init.OwnAddress2 = 0;
  hi2c1.Init.OwnAddress2Masks = I2C_OA2_NOMASK;
  hi2c1.Init.GeneralCallMode = I2C_GENERALCALL_DISABLE;
  hi2c1.Init.NoStretchMode = I2C_NOSTRETCH_DISABLE;
  if (HAL_I2C_Init(&hi2c1) != HAL_OK)
  {
    Error_Handler();
  }

  /** Configure Analogue filter
  */
  if (HAL_I2CEx_ConfigAnalogFilter(&hi2c1, I2C_ANALOGFILTER_ENABLE) != HAL_OK)
  {
    Error_Handler();
  }

  /** Configure Digital filter
  */
  if (HAL_I2CEx_ConfigDigitalFilter(&hi2c1, 0) != HAL_OK)
  {
    Error_Handler();
  }

}

static void MX_I2C5_Init(void)
{

  hi2c5.Instance = I2C5;
  hi2c5.Init.Timing = 0x307075B1;
  hi2c5.Init.OwnAddress1 = 0;
  hi2c5.Init.AddressingMode = I2C_ADDRESSINGMODE_7BIT;
  hi2c5.Init.DualAddressMode = I2C_DUALADDRESS_DISABLE;
  hi2c5.Init.OwnAddress2 = 0;
  hi2c5.Init.OwnAddress2Masks = I2C_OA2_NOMASK;
  hi2c5.Init.GeneralCallMode = I2C_GENERALCALL_DISABLE;
  hi2c5.Init.NoStretchMode = I2C_NOSTRETCH_DISABLE;
  if (HAL_I2C_Init(&hi2c5) != HAL_OK)
  {
    Error_Handler();
  }

  /** Configure Analogue filter
  */
  if (HAL_I2CEx_ConfigAnalogFilter(&hi2c5, I2C_ANALOGFILTER_ENABLE) != HAL_OK)
  {
    Error_Handler();
  }

  /** Configure Digital filter
  */
  if (HAL_I2CEx_ConfigDigitalFilter(&hi2c5, 0) != HAL_OK)
  {
    Error_Handler();
  }

}

static void MX_RTC_Init(void)
{

  RTC_TimeTypeDef sTime = {0};
  RTC_DateTypeDef sDate = {0};

  /** Initialize RTC Only
  */
  hrtc.Instance = RTC;
  hrtc.Init.HourFormat = RTC_HOURFORMAT_24;
  hrtc.Init.AsynchPrediv = 127;
  hrtc.Init.SynchPrediv = 6249;
  hrtc.Init.OutPut = RTC_OUTPUT_DISABLE;
  hrtc.Init.OutPutPolarity = RTC_OUTPUT_POLARITY_HIGH;
  hrtc.Init.OutPutType = RTC_OUTPUT_TYPE_OPENDRAIN;
  hrtc.Init.OutPutRemap = RTC_OUTPUT_REMAP_NONE;
  if (HAL_RTC_Init(&hrtc) != HAL_OK)
  {
    Error_Handler();
  }

  /** Initialize RTC and set the Time and Date
  */
  sTime.Hours = 0;
  sTime.Minutes = 0;
  sTime.Seconds = 0;
  sTime.DayLightSaving = RTC_DAYLIGHTSAVING_NONE;
  sTime.StoreOperation = RTC_STOREOPERATION_RESET;
  if (HAL_RTC_SetTime(&hrtc, &sTime, RTC_FORMAT_BIN) != HAL_OK)
  {
    Error_Handler();
  }
  sDate.WeekDay = RTC_WEEKDAY_MONDAY;
  sDate.Month = RTC_MONTH_JANUARY;
  sDate.Date = 1;
  sDate.Year = 0;

  if (HAL_RTC_SetDate(&hrtc, &sDate, RTC_FORMAT_BIN) != HAL_OK)
  {
    Error_Handler();
  }

}

static void MX_SPI1_Init(void)
{

  /* SPI1 parameter configuration*/
  hspi1.Instance = SPI1;
  hspi1.Init.Mode = SPI_MODE_MASTER;
  hspi1.Init.Direction = SPI_DIRECTION_2LINES;
  hspi1.Init.DataSize = SPI_DATASIZE_8BIT;
  hspi1.Init.CLKPolarity = SPI_POLARITY_LOW;
  hspi1.Init.CLKPhase = SPI_PHASE_1EDGE;
  hspi1.Init.NSS = SPI_NSS_SOFT;
  hspi1.Init.BaudRatePrescaler = SPI_BAUDRATEPRESCALER_32;
  hspi1.Init.FirstBit = SPI_FIRSTBIT_MSB;
  hspi1.Init.TIMode = SPI_TIMODE_DISABLE;
  hspi1.Init.CRCCalculation = SPI_CRCCALCULATION_DISABLE;
  hspi1.Init.CRCPolynomial = 0x0;
  hspi1.Init.NSSPMode = SPI_NSS_PULSE_ENABLE;
  hspi1.Init.NSSPolarity = SPI_NSS_POLARITY_LOW;
  hspi1.Init.FifoThreshold = SPI_FIFO_THRESHOLD_01DATA;
  hspi1.Init.TxCRCInitializationPattern = SPI_CRC_INITIALIZATION_ALL_ZERO_PATTERN;
  hspi1.Init.RxCRCInitializationPattern = SPI_CRC_INITIALIZATION_ALL_ZERO_PATTERN;
  hspi1.Init.MasterSSIdleness = SPI_MASTER_SS_IDLENESS_00CYCLE;
  hspi1.Init.MasterInterDataIdleness = SPI_MASTER_INTERDATA_IDLENESS_00CYCLE;
  hspi1.Init.MasterReceiverAutoSusp = SPI_MASTER_RX_AUTOSUSP_DISABLE;
  hspi1.Init.MasterKeepIOState = SPI_MASTER_KEEP_IO_STATE_DISABLE;
  hspi1.Init.IOSwap = SPI_IO_SWAP_DISABLE;
  if (HAL_SPI_Init(&hspi1) != HAL_OK)
  {
    Error_Handler();
  }

}

static void MX_SPI2_Init(void)
{

  /* SPI2 parameter configuration*/
  hspi2.Instance = SPI2;
  hspi2.Init.Mode = SPI_MODE_MASTER;
  hspi2.Init.Direction = SPI_DIRECTION_2LINES;
  hspi2.Init.DataSize = SPI_DATASIZE_8BIT;
  hspi2.Init.CLKPolarity = SPI_POLARITY_LOW;
  hspi2.Init.CLKPhase = SPI_PHASE_2EDGE;
  hspi2.Init.NSS = SPI_NSS_SOFT;
  hspi2.Init.BaudRatePrescaler = SPI_BAUDRATEPRESCALER_256;
  hspi2.Init.FirstBit = SPI_FIRSTBIT_MSB;
  hspi2.Init.TIMode = SPI_TIMODE_DISABLE;
  hspi2.Init.CRCCalculation = SPI_CRCCALCULATION_DISABLE;
  hspi2.Init.CRCPolynomial = 0x0;
  hspi2.Init.NSSPMode = SPI_NSS_PULSE_ENABLE;
  hspi2.Init.NSSPolarity = SPI_NSS_POLARITY_LOW;
  hspi2.Init.FifoThreshold = SPI_FIFO_THRESHOLD_01DATA;
  hspi2.Init.TxCRCInitializationPattern = SPI_CRC_INITIALIZATION_ALL_ZERO_PATTERN;
  hspi2.Init.RxCRCInitializationPattern = SPI_CRC_INITIALIZATION_ALL_ZERO_PATTERN;
  hspi2.Init.MasterSSIdleness = SPI_MASTER_SS_IDLENESS_00CYCLE;
  hspi2.Init.MasterInterDataIdleness = SPI_MASTER_INTERDATA_IDLENESS_00CYCLE;
  hspi2.Init.MasterReceiverAutoSusp = SPI_MASTER_RX_AUTOSUSP_DISABLE;
  hspi2.Init.MasterKeepIOState = SPI_MASTER_KEEP_IO_STATE_DISABLE;
  hspi2.Init.IOSwap = SPI_IO_SWAP_DISABLE;
  if (HAL_SPI_Init(&hspi2) != HAL_OK)
  {
    Error_Handler();
  }

}

static void MX_SPI3_Init(void)
{

  /* SPI3 parameter configuration*/
  hspi3.Instance = SPI3;
  hspi3.Init.Mode = SPI_MODE_MASTER;
  hspi3.Init.Direction = SPI_DIRECTION_2LINES;
  hspi3.Init.DataSize = SPI_DATASIZE_8BIT;
  hspi3.Init.CLKPolarity = SPI_POLARITY_LOW;
  hspi3.Init.CLKPhase = SPI_PHASE_1EDGE;
  hspi3.Init.NSS = SPI_NSS_SOFT;
  hspi3.Init.BaudRatePrescaler = SPI_BAUDRATEPRESCALER_128;
  hspi3.Init.FirstBit = SPI_FIRSTBIT_MSB;
  hspi3.Init.TIMode = SPI_TIMODE_DISABLE;
  hspi3.Init.CRCCalculation = SPI_CRCCALCULATION_DISABLE;
  hspi3.Init.CRCPolynomial = 0x0;
  hspi3.Init.NSSPMode = SPI_NSS_PULSE_ENABLE;
  hspi3.Init.NSSPolarity = SPI_NSS_POLARITY_LOW;
  hspi3.Init.FifoThreshold = SPI_FIFO_THRESHOLD_01DATA;
  hspi3.Init.TxCRCInitializationPattern = SPI_CRC_INITIALIZATION_ALL_ZERO_PATTERN;
  hspi3.Init.RxCRCInitializationPattern = SPI_CRC_INITIALIZATION_ALL_ZERO_PATTERN;
  hspi3.Init.MasterSSIdleness = SPI_MASTER_SS_IDLENESS_00CYCLE;
  hspi3.Init.MasterInterDataIdleness = SPI_MASTER_INTERDATA_IDLENESS_00CYCLE;
  hspi3.Init.MasterReceiverAutoSusp = SPI_MASTER_RX_AUTOSUSP_DISABLE;
  hspi3.Init.MasterKeepIOState = SPI_MASTER_KEEP_IO_STATE_DISABLE;
  hspi3.Init.IOSwap = SPI_IO_SWAP_DISABLE;
  if (HAL_SPI_Init(&hspi3) != HAL_OK)
  {
    Error_Handler();
  }

}

static void MX_SPI4_Init(void)
{

  /* SPI4 parameter configuration*/
  hspi4.Instance = SPI4;
  hspi4.Init.Mode = SPI_MODE_MASTER;
  hspi4.Init.Direction = SPI_DIRECTION_2LINES;
  hspi4.Init.DataSize = SPI_DATASIZE_8BIT;
  hspi4.Init.CLKPolarity = SPI_POLARITY_HIGH;
  hspi4.Init.CLKPhase = SPI_PHASE_2EDGE;
  hspi4.Init.NSS = SPI_NSS_SOFT;
  hspi4.Init.BaudRatePrescaler = SPI_BAUDRATEPRESCALER_128;
  hspi4.Init.FirstBit = SPI_FIRSTBIT_MSB;
  hspi4.Init.TIMode = SPI_TIMODE_DISABLE;
  hspi4.Init.CRCCalculation = SPI_CRCCALCULATION_DISABLE;
  hspi4.Init.CRCPolynomial = 0x0;
  hspi4.Init.NSSPMode = SPI_NSS_PULSE_ENABLE;
  hspi4.Init.NSSPolarity = SPI_NSS_POLARITY_LOW;
  hspi4.Init.FifoThreshold = SPI_FIFO_THRESHOLD_01DATA;
  hspi4.Init.TxCRCInitializationPattern = SPI_CRC_INITIALIZATION_ALL_ZERO_PATTERN;
  hspi4.Init.RxCRCInitializationPattern = SPI_CRC_INITIALIZATION_ALL_ZERO_PATTERN;
  hspi4.Init.MasterSSIdleness = SPI_MASTER_SS_IDLENESS_00CYCLE;
  hspi4.Init.MasterInterDataIdleness = SPI_MASTER_INTERDATA_IDLENESS_00CYCLE;
  hspi4.Init.MasterReceiverAutoSusp = SPI_MASTER_RX_AUTOSUSP_DISABLE;
  hspi4.Init.MasterKeepIOState = SPI_MASTER_KEEP_IO_STATE_DISABLE;
  hspi4.Init.IOSwap = SPI_IO_SWAP_DISABLE;
  if (HAL_SPI_Init(&hspi4) != HAL_OK)
  {
    Error_Handler();
  }

}

static void MX_SPI5_Init(void)
{

  /* SPI5 parameter configuration*/
  hspi5.Instance = SPI5;
  hspi5.Init.Mode = SPI_MODE_MASTER;
  hspi5.Init.Direction = SPI_DIRECTION_2LINES;
  hspi5.Init.DataSize = SPI_DATASIZE_8BIT;
  hspi5.Init.CLKPolarity = SPI_POLARITY_LOW;
  hspi5.Init.CLKPhase = SPI_PHASE_1EDGE;
  hspi5.Init.NSS = SPI_NSS_SOFT;
  hspi5.Init.BaudRatePrescaler = SPI_BAUDRATEPRESCALER_128;
  hspi5.Init.FirstBit = SPI_FIRSTBIT_MSB;
  hspi5.Init.TIMode = SPI_TIMODE_DISABLE;
  hspi5.Init.CRCCalculation = SPI_CRCCALCULATION_DISABLE;
  hspi5.Init.CRCPolynomial = 0x0;
  hspi5.Init.NSSPMode = SPI_NSS_PULSE_ENABLE;
  hspi5.Init.NSSPolarity = SPI_NSS_POLARITY_LOW;
  hspi5.Init.FifoThreshold = SPI_FIFO_THRESHOLD_01DATA;
  hspi5.Init.TxCRCInitializationPattern = SPI_CRC_INITIALIZATION_ALL_ZERO_PATTERN;
  hspi5.Init.RxCRCInitializationPattern = SPI_CRC_INITIALIZATION_ALL_ZERO_PATTERN;
  hspi5.Init.MasterSSIdleness = SPI_MASTER_SS_IDLENESS_00CYCLE;
  hspi5.Init.MasterInterDataIdleness = SPI_MASTER_INTERDATA_IDLENESS_00CYCLE;
  hspi5.Init.MasterReceiverAutoSusp = SPI_MASTER_RX_AUTOSUSP_DISABLE;
  hspi5.Init.MasterKeepIOState = SPI_MASTER_KEEP_IO_STATE_DISABLE;
  hspi5.Init.IOSwap = SPI_IO_SWAP_DISABLE;
  if (HAL_SPI_Init(&hspi5) != HAL_OK)
  {
    Error_Handler();
  }

}

static void MX_SPI6_Init(void)
{

  /* SPI6 parameter configuration*/
  hspi6.Instance = SPI6;
  hspi6.Init.Mode = SPI_MODE_MASTER;
  hspi6.Init.Direction = SPI_DIRECTION_2LINES;
  hspi6.Init.DataSize = SPI_DATASIZE_8BIT;
  hspi6.Init.CLKPolarity = SPI_POLARITY_LOW;
  hspi6.Init.CLKPhase = SPI_PHASE_1EDGE;
  hspi6.Init.NSS = SPI_NSS_SOFT;
  hspi6.Init.BaudRatePrescaler = SPI_BAUDRATEPRESCALER_128;
  hspi6.Init.FirstBit = SPI_FIRSTBIT_MSB;
  hspi6.Init.TIMode = SPI_TIMODE_DISABLE;
  hspi6.Init.CRCCalculation = SPI_CRCCALCULATION_DISABLE;
  hspi6.Init.CRCPolynomial = 0x0;
  hspi6.Init.NSSPMode = SPI_NSS_PULSE_ENABLE;
  hspi6.Init.NSSPolarity = SPI_NSS_POLARITY_LOW;
  hspi6.Init.FifoThreshold = SPI_FIFO_THRESHOLD_01DATA;
  hspi6.Init.TxCRCInitializationPattern = SPI_CRC_INITIALIZATION_ALL_ZERO_PATTERN;
  hspi6.Init.RxCRCInitializationPattern = SPI_CRC_INITIALIZATION_ALL_ZERO_PATTERN;
  hspi6.Init.MasterSSIdleness = SPI_MASTER_SS_IDLENESS_00CYCLE;
  hspi6.Init.MasterInterDataIdleness = SPI_MASTER_INTERDATA_IDLENESS_00CYCLE;
  hspi6.Init.MasterReceiverAutoSusp = SPI_MASTER_RX_AUTOSUSP_DISABLE;
  hspi6.Init.MasterKeepIOState = SPI_MASTER_KEEP_IO_STATE_DISABLE;
  hspi6.Init.IOSwap = SPI_IO_SWAP_DISABLE;
  if (HAL_SPI_Init(&hspi6) != HAL_OK)
  {
    Error_Handler();
  }

}

static void MX_TIM14_Init(void)
{

  htim14.Instance = TIM14;
  htim14.Init.Prescaler = 0;
  htim14.Init.CounterMode = TIM_COUNTERMODE_UP;
  htim14.Init.Period = 65535;
  htim14.Init.ClockDivision = TIM_CLOCKDIVISION_DIV1;
  htim14.Init.AutoReloadPreload = TIM_AUTORELOAD_PRELOAD_DISABLE;
  if (HAL_TIM_Base_Init(&htim14) != HAL_OK)
  {
    Error_Handler();
  }

}

static void MX_USART10_UART_Init(void)
{

  huart10.Instance = USART10;
  huart10.Init.BaudRate = 38400;
  huart10.Init.WordLength = UART_WORDLENGTH_8B;
  huart10.Init.StopBits = UART_STOPBITS_1;
  huart10.Init.Parity = UART_PARITY_NONE;
  huart10.Init.Mode = UART_MODE_TX_RX;
  huart10.Init.HwFlowCtl = UART_HWCONTROL_NONE;
  huart10.Init.OverSampling = UART_OVERSAMPLING_16;
  huart10.Init.OneBitSampling = UART_ONE_BIT_SAMPLE_DISABLE;
  huart10.Init.ClockPrescaler = UART_PRESCALER_DIV1;
  huart10.AdvancedInit.AdvFeatureInit = UART_ADVFEATURE_NO_INIT;
  if (HAL_UART_Init(&huart10) != HAL_OK)
  {
    Error_Handler();
  }
  if (HAL_UARTEx_SetTxFifoThreshold(&huart10, UART_TXFIFO_THRESHOLD_1_8) != HAL_OK)
  {
    Error_Handler();
  }
  if (HAL_UARTEx_SetRxFifoThreshold(&huart10, UART_RXFIFO_THRESHOLD_1_8) != HAL_OK)
  {
    Error_Handler();
  }
  if (HAL_UARTEx_EnableFifoMode(&huart10) != HAL_OK)
  {
    Error_Handler();
  }

}

static void MX_GPIO_Init(void)
{
  GPIO_InitTypeDef GPIO_InitStruct = {0};

  /* GPIO Ports Clock Enable */
  __HAL_RCC_GPIOE_CLK_ENABLE();
  __HAL_RCC_GPIOC_CLK_ENABLE();
  __HAL_RCC_GPIOF_CLK_ENABLE();
  __HAL_RCC_GPIOH_CLK_ENABLE();
  __HAL_RCC_GPIOA_CLK_ENABLE();
  __HAL_RCC_GPIOB_CLK_ENABLE();
  __HAL_RCC_GPIOD_CLK_ENABLE();
  __HAL_RCC_GPIOG_CLK_ENABLE();

  /*Configure GPIO pin Output Level */
  HAL_GPIO_WritePin(GPIOE, GPS_NRST_Pin|ADC_CS_Pin, GPIO_PIN_SET);

  /*Configure GPIO pin Output Level */
  HAL_GPIO_WritePin(RADIO_CS_GPIO_Port, RADIO_CS_Pin, GPIO_PIN_SET);

  /*Configure GPIO pin Output Level */
  HAL_GPIO_WritePin(RF_NSRT_GPIO_Port, RF_NSRT_Pin, GPIO_PIN_SET);

  /*Configure GPIO pin Output Level */
  HAL_GPIO_WritePin(GPIOA, BAR2_CS_Pin|BAR1_CS_Pin, GPIO_PIN_SET);

  /*Configure GPIO pin Output Level */
  HAL_GPIO_WritePin(ETH_NRST_GPIO_Port, ETH_NRST_Pin, GPIO_PIN_SET);

  /*Configure GPIO pin Output Level */
  HAL_GPIO_WritePin(GPIOF, PDB_DIO1_Pin|PDB_DIO2_Pin, GPIO_PIN_RESET);

  /*Configure GPIO pin Output Level */
  HAL_GPIO_WritePin(GPIOD, TC1_CS_Pin|TC2_CS_Pin, GPIO_PIN_SET);

  /*Configure GPIO pin Output Level */
  HAL_GPIO_WritePin(VLV3_EN_GPIO_Port, VLV3_EN_Pin, GPIO_PIN_RESET);

  /*Configure GPIO pin Output Level */
  HAL_GPIO_WritePin(VLV1_EN_GPIO_Port, VLV1_EN_Pin, GPIO_PIN_RESET);

  /*Configure GPIO pin Output Level */
  HAL_GPIO_WritePin(GPIOA, VLV2_EN_Pin|BUFF_CLR_Pin|BUFF_CLK_Pin|VLV_CTRL_Pin, GPIO_PIN_RESET);

  /*Configure GPIO pin Output Level */
  HAL_GPIO_WritePin(GPIOG, FLASH_CS_Pin|EEPROM_WC_Pin, GPIO_PIN_SET);

  /*Configure GPIO pin Output Level */
  HAL_GPIO_WritePin(GPIOB, BUZZ_Pin|LED_RED_Pin, GPIO_PIN_RESET);

  /*Configure GPIO pin Output Level */
  HAL_GPIO_WritePin(GPIOE, LED_GREEN_Pin|LED_BLUE_Pin, GPIO_PIN_RESET);

  /*Configure GPIO pins : GPS_NRST_Pin ADC_CS_Pin LED_GREEN_Pin LED_BLUE_Pin */
  GPIO_InitStruct.Pin = GPS_NRST_Pin|ADC_CS_Pin|LED_GREEN_Pin|LED_BLUE_Pin;
  GPIO_InitStruct.Mode = GPIO_MODE_OUTPUT_PP;
  GPIO_InitStruct.Pull = GPIO_NOPULL;
  GPIO_InitStruct.Speed = GPIO_SPEED_FREQ_LOW;
  HAL_GPIO_Init(GPIOE, &GPIO_InitStruct);

  /*Configure GPIO pins : RF_DIO3_Pin RF_DIO2_Pin RF_DIO1_Pin RF_MODE_SW_Pin
                           VLV3_OLD_Pin VLV1_OLD_Pin */
  GPIO_InitStruct.Pin = RF_DIO3_Pin|RF_DIO2_Pin|RF_DIO1_Pin|RF_MODE_SW_Pin
                          |VLV3_OLD_Pin|VLV1_OLD_Pin;
  GPIO_InitStruct.Mode = GPIO_MODE_INPUT;
  GPIO_InitStruct.Pull = GPIO_NOPULL;
  HAL_GPIO_Init(GPIOC, &GPIO_InitStruct);

  /*Configure GPIO pins : RADIO_CS_Pin PDB_DIO1_Pin PDB_DIO2_Pin */
  GPIO_InitStruct.Pin = RADIO_CS_Pin|PDB_DIO1_Pin|PDB_DIO2_Pin;
  GPIO_InitStruct.Mode = GPIO_MODE_OUTPUT_PP;
  GPIO_InitStruct.Pull = GPIO_NOPULL;
  GPIO_InitStruct.Speed = GPIO_SPEED_FREQ_LOW;
  HAL_GPIO_Init(GPIOF, &GPIO_InitStruct);

  /*Configure GPIO pin : RF_BUSY_Pin */
  GPIO_InitStruct.Pin = RF_BUSY_Pin;
  GPIO_InitStruct.Mode = GPIO_MODE_INPUT;
  GPIO_InitStruct.Pull = GPIO_NOPULL;
  HAL_GPIO_Init(RF_BUSY_GPIO_Port, &GPIO_InitStruct);

  /*Configure GPIO pins : RF_NSRT_Pin VLV1_EN_Pin */
  GPIO_InitStruct.Pin = RF_NSRT_Pin|VLV1_EN_Pin;
  GPIO_InitStruct.Mode = GPIO_MODE_OUTPUT_PP;
  GPIO_InitStruct.Pull = GPIO_NOPULL;
  GPIO_InitStruct.Speed = GPIO_SPEED_FREQ_LOW;
  HAL_GPIO_Init(GPIOC, &GPIO_InitStruct);

  /*Configure GPIO pins : BAR2_CS_Pin BAR1_CS_Pin VLV2_EN_Pin */
  GPIO_InitStruct.Pin = BAR2_CS_Pin|BAR1_CS_Pin|VLV2_EN_Pin;
  GPIO_InitStruct.Mode = GPIO_MODE_OUTPUT_PP;
  GPIO_InitStruct.Pull = GPIO_NOPULL;
  GPIO_InitStruct.Speed = GPIO_SPEED_FREQ_LOW;
  HAL_GPIO_Init(GPIOA, &GPIO_InitStruct);

  /*Configure GPIO pins : ETH_NRST_Pin BUZZ_Pin LED_RED_Pin */
  GPIO_InitStruct.Pin = ETH_NRST_Pin|BUZZ_Pin|LED_RED_Pin;
  GPIO_InitStruct.Mode = GPIO_MODE_OUTPUT_PP;
  GPIO_InitStruct.Pull = GPIO_NOPULL;
  GPIO_InitStruct.Speed = GPIO_SPEED_FREQ_LOW;
  HAL_GPIO_Init(GPIOB, &GPIO_InitStruct);

  /*Configure GPIO pin : VLV2_OLD_Pin */
  GPIO_InitStruct.Pin = VLV2_OLD_Pin;
  GPIO_InitStruct.Mode = GPIO_MODE_INPUT;
  GPIO_InitStruct.Pull = GPIO_NOPULL;
  HAL_GPIO_Init(VLV2_OLD_GPIO_Port, &GPIO_InitStruct);

  /*Configure GPIO pins : TC1_CS_Pin TC2_CS_Pin */
  GPIO_InitStruct.Pin = TC1_CS_Pin|TC2_CS_Pin;
  GPIO_InitStruct.Mode = GPIO_MODE_OUTPUT_PP;
  GPIO_InitStruct.Pull = GPIO_NOPULL;
  GPIO_InitStruct.Speed = GPIO_SPEED_FREQ_LOW;
  HAL_GPIO_Init(GPIOD, &GPIO_InitStruct);

  /*Configure GPIO pins : VLV3_EN_Pin FLASH_CS_Pin EEPROM_WC_Pin */
  GPIO_InitStruct.Pin = VLV3_EN_Pin|FLASH_CS_Pin|EEPROM_WC_Pin;
  GPIO_InitStruct.Mode = GPIO_MODE_OUTPUT_PP;
  GPIO_InitStruct.Pull = GPIO_NOPULL;
  GPIO_InitStruct.Speed = GPIO_SPEED_FREQ_LOW;
  HAL_GPIO_Init(GPIOG, &GPIO_InitStruct);

  /*Configure GPIO pins : BUFF_CLR_Pin BUFF_CLK_Pin VLV_CTRL_Pin */
  GPIO_InitStruct.Pin = BUFF_CLR_Pin|BUFF_CLK_Pin|VLV_CTRL_Pin;
  GPIO_InitStruct.Mode = GPIO_MODE_OUTPUT_PP;
  GPIO_InitStruct.Pull = GPIO_NOPULL;
  GPIO_InitStruct.Speed = GPIO_SPEED_FREQ_VERY_HIGH;
  HAL_GPIO_Init(GPIOA, &GPIO_InitStruct);

  /*Configure GPIO pins : IMU1_INT1_Pin IMU1_INT2_Pin IMU2_INT1_Pin IMU2_INT2_Pin */
  GPIO_InitStruct.Pin = IMU1_INT1_Pin|IMU1_INT2_Pin|IMU2_INT1_Pin|IMU2_INT2_Pin;
  GPIO_InitStruct.Mode = GPIO_MODE_INPUT;
  GPIO_InitStruct.Pull = GPIO_NOPULL;
  HAL_GPIO_Init(GPIOD, &GPIO_InitStruct);

  /*AnalogSwitch Config */
  HAL_SYSCFG_AnalogSwitchConfig(SYSCFG_SWITCH_PC2, SYSCFG_SWITCH_PC2_CLOSE);

}

/* USER CODE BEGIN 4 */
void HAL_UART_RxCpltCallback(UART_HandleTypeDef *huart) {
    if(huart->Instance == USART10) {
        irq_gps_callback(&(sensors_h.gps_h));
    }
}

void HAL_UART_ErrorCallback(UART_HandleTypeDef *huart) {
    if(huart->Instance == USART10) {
    	irq_gps_error_callback(&(sensors_h.gps_h));
    }
}
/* USER CODE END 4 */

void StartAndMonitor(void *argument)
{
  /* init code for LWIP */
  MX_LWIP_Init();
  /* USER CODE BEGIN 5 */
  osDelay(1);
  	// Signal end of critical section
	if(is_net_logging_up()) {
		// No UDP error
		start_led_timer(1, 0, 0);
	}
	else {
		// UDP error
		start_led_timer(250, UINT32_MAX, 1);
	}

	//HAL_GPIO_WritePin(BUZZ_GPIO_Port, BUZZ_Pin, 1);
	start_buzz_timer(1000, 0, 0, 1);

	// Setup TCP server
	if(server_create(loaded_config.limewireIP, loaded_config.bayboard1IP, loaded_config.bayboard2IP, loaded_config.bayboard3IP, loaded_config.flightrecordIP)) {
		// memory error creating TCP server, TCP server will not start
		log_message(FC_ERR_CREAT_TCP_MEM_ERR, -1);
	}

	setup_system_state();

	// Config SR
  	Shift_Reg reg = {0};
  	reg.VLV_CTR_GPIO_Port = VLV_CTRL_GPIO_Port;
  	reg.VLV_CTR_GPIO_Pin = VLV_CTRL_Pin;
  	reg.VLV_CLK_GPIO_Port = BUFF_CLK_GPIO_Port;
  	reg.VLV_CLK_GPIO_Pin = BUFF_CLK_Pin;
  	reg.VLV_CLR_GPIO_Port = BUFF_CLR_GPIO_Port;
  	reg.VLV_CLR_GPIO_Pin = BUFF_CLR_Pin;

  	VLV_Set_Conf(reg, loaded_config.vlv1_en, loaded_config.vlv1_v, loaded_config.vlv2_en, loaded_config.vlv2_v, loaded_config.vlv3_en, loaded_config.vlv3_v);

  	// Load valve pins
  	setup_valve(0, VLV1_EN_GPIO_Port, VLV1_EN_Pin, VLV1_OLD_GPIO_Port, VLV1_OLD_Pin);
  	setup_valve(1, VLV2_EN_GPIO_Port, VLV2_EN_Pin, VLV2_OLD_GPIO_Port, VLV2_OLD_Pin);
  	setup_valve(2, VLV3_EN_GPIO_Port, VLV3_EN_Pin, VLV3_OLD_GPIO_Port, VLV3_OLD_Pin);

	// Init sensors and peripherals
  	// ADC
  	sensors_h.adc_h.MAX11128_CS_PORT = ADC_CS_GPIO_Port;
  	sensors_h.adc_h.MAX11128_CS_ADDR = ADC_CS_Pin;
  	sensors_h.adc_h.HARDWARE_CONFIGURATION = NO_EOC_NOR_CNVST;
  	sensors_h.adc_h.NUM_CHANNELS = 16;

  	init_adc(&hspi4, &(sensors_h.adc_h));
  	// Check to make sure the chip is connected
	uint16_t adc_values[16] = {0};
	read_adc(&hspi4, &(sensors_h.adc_h), adc_values);
	if(adc_values[ADC_3V3_BUS_I] == 0) { // 3v3 bus voltage should always be greater than 0
		log_message(FC_ERR_SING_ADC_INIT, -1);
	}

  	// TC ADCs
  	ADS_configTC(&(sensors_h.TCs[2]), &hspi2, GPIOB, GPIO_PIN_14, PERIPHERAL_TIMEOUT, TC1_CS_GPIO_Port, TC1_CS_Pin, ADS_MUX_AIN0_AIN1, loaded_config.tc1_gain, ADS_DATA_RATE_600);
  	ADS_configTC(&(sensors_h.TCs[1]), &hspi2, GPIOB, GPIO_PIN_14, PERIPHERAL_TIMEOUT, TC1_CS_GPIO_Port, TC1_CS_Pin, ADS_MUX_AIN2_AIN3, loaded_config.tc2_gain, ADS_DATA_RATE_600);
  	ADS_configTC(&(sensors_h.TCs[0]), &hspi2, GPIOB, GPIO_PIN_14, PERIPHERAL_TIMEOUT, TC2_CS_GPIO_Port, TC2_CS_Pin, ADS_MUX_AIN0_AIN1, loaded_config.tc3_gain, ADS_DATA_RATE_600);

  	if(ADS_init(&(sensors_h.tc_main_h), sensors_h.TCs, 3)) {
  		// ADS thread start error
  		log_message(ERR_ADS_INIT_THREAD_ERR, -1);
  	}

  	// IMUs
  	sensors_h.imu1_h.hi2c = &hi2c5;
  	sensors_h.imu1_h.I2C_TIMEOUT = PERIPHERAL_TIMEOUT;
  	sensors_h.imu1_h.XL_x_offset = 0;
  	sensors_h.imu1_h.XL_y_offset = 0;
  	sensors_h.imu1_h.XL_z_offset = 0;
  	sensors_h.imu1_h.G_x_offset = 0;
  	sensors_h.imu1_h.G_y_offset = 0;
  	sensors_h.imu1_h.G_z_offset = 0;
  	sensors_h.imu1_h.SA0 = 0;

  	sensors_h.imu2_h.hi2c = &hi2c5;
  	sensors_h.imu2_h.I2C_TIMEOUT = PERIPHERAL_TIMEOUT;
  	sensors_h.imu2_h.XL_x_offset = 0;
  	sensors_h.imu2_h.XL_y_offset = 0;
  	sensors_h.imu2_h.XL_z_offset = 0;
  	sensors_h.imu2_h.G_x_offset = 0;
  	sensors_h.imu2_h.G_y_offset = 0;
  	sensors_h.imu2_h.G_z_offset = 0;
  	sensors_h.imu2_h.SA0 = 1;

  	if(IMU_init(&(sensors_h.imu1_h)) == -1) {
  		// IMU 1 init error
  		log_message(ERR_IMU_INIT "1", -1);
  	}
  	if(IMU_init(&(sensors_h.imu2_h)) == -1) {
  		// IMU 2 init error
  		log_message(ERR_IMU_INIT "2", -1);
  	}

  	// Barometers
  	sensors_h.bar1_h.hspi = &hspi6;
  	sensors_h.bar1_h.SPI_TIMEOUT = PERIPHERAL_TIMEOUT;
  	sensors_h.bar1_h.CS_GPIO_Port = BAR1_CS_GPIO_Port;
  	sensors_h.bar1_h.CS_GPIO_Pin = BAR1_CS_Pin;
  	sensors_h.bar1_h.pres_offset = 0;
  	sensors_h.bar1_h.alt_offset = 0;

  	sensors_h.bar2_h.hspi = &hspi6;
  	sensors_h.bar2_h.SPI_TIMEOUT = PERIPHERAL_TIMEOUT;
  	sensors_h.bar2_h.CS_GPIO_Port = BAR2_CS_GPIO_Port;
  	sensors_h.bar2_h.CS_GPIO_Pin = BAR2_CS_Pin;
  	sensors_h.bar2_h.pres_offset = 0;
  	sensors_h.bar2_h.alt_offset = 0;

  	if(MS5611_Reset(&(sensors_h.bar1_h))) {
  		// Bar 1 init error
  		log_message(ERR_BAR_INIT "1", -1);
  	}
  	MS5611_readPROM(&(sensors_h.bar1_h), &(sensors_h.prom1));

  	if(MS5611_Reset(&(sensors_h.bar2_h))) {
  		// Bar 2 init error
  		log_message(ERR_BAR_INIT "2", -1);
  	}
  	MS5611_readPROM(&(sensors_h.bar2_h), &(sensors_h.prom2));

  	// Init GPS
  	SemaphoreHandle_t gpsSemaphore = xSemaphoreCreateBinary();
  	xSemaphoreTake(gpsSemaphore, 0);
  	sensors_h.gps_h.semaphore = gpsSemaphore;
  	sensors_h.gps_h.huart = &huart10;

  	// Init radio
  	radio_config.spiHandle = &hspi5;
  	radio_config.nssPort = RADIO_CS_GPIO_Port;
  	radio_config.nssPin = RADIO_CS_Pin;
  	radio_config.resetPort = RF_NSRT_GPIO_Port;
  	radio_config.resetPin = RF_NSRT_Pin;
  	radio_config.busyPort = RF_BUSY_GPIO_Port;
  	radio_config.busyPin = RF_BUSY_Pin;

  	if(!setup_radio(HAL_GPIO_ReadPin(RF_MODE_SW_GPIO_Port, RF_MODE_SW_Pin) == GPIO_PIN_SET, &radio_config)) {
  		log_message(FC_ERR_RADIO_INIT_FAILED, -1);
  	}

  	Autos_boot_t boot_params = {0};
  	if(!read_autosequence_params((void *) &boot_params, sizeof(Autos_boot_t))) {
  		log_message(ERR_TFTP_EEPROM_READ_ERR, -1);
  		memset(&boot_params, 0, sizeof(Autos_boot_t));
  	}

	// Start tasks

  	// Start UDP telemetry processing
  	telemetryUDPTaskHandle = osThreadNew(TelemetryUDPProcess, NULL, &telemetry_udp_task_attr);

  	// Start telemetry task
  	telemetryTaskHandle = osThreadNew(TelemetryTask, NULL, &telemetry_task_attr);

  	// Start packet handler
  	packetTaskHandle = osThreadNew(ProcessPackets, NULL, &packet_task_attr);

  	// Start autosequence task
  	autosequenceTaskHandle = osThreadNew(AutosequenceTask, (void *)&boot_params, &autosequence_task_attr);

  	// Start radio broadcasting
  	radioTaskHandle = osThreadNew(BroadcastRadio, NULL, &radio_task_attr);

  	// Start TCP server only if the ethernet link is up

	if(netif_is_link_up(&gnetif)) {
		switch(server_init()) {
			case 0: {
				// TCP server started
				log_message(FC_STAT_TCP_SERV_RUNNING, -1);
				break;
			}
			case -1: {
				break;
			}
			case -2: {
				// one of the threads failed to start
				log_message(FC_ERR_INIT_TCP_THREAD_ERR, -1);
				break;
			}
			case -3: {
				break;
			}
			default: {
				break;
			}
		}
	}
	// log startup done
	log_message(STAT_STARTUP_DONE, -1);

	/*
	 * ALL VALVE STATES SHOULD BE SENT ON THE START OF CONNECTION WITH LIMEWIRE (FC FOR BBs) (WHEN THE FC CONNECTS TO LIMEWIRE SEND THE VALVE STATES FOR THE ENTIRE ROCKET)
	 *
	 * fc telemetry comes from struct, sent on a 50hz loop
	 * bb telemetry comes from tcp packets, relayed to limewire and stored for optional access in autosequences
	 * fc valve states are sent after valve commands are sent, then stored for optional access
	 * bb valve states are relayed from tcp packets, and saved for optional access
	 * all valve commands are processed when received. fc relays commands from limewire to bb
	 *
	 * telemetry task - read from peripherals and send telemetry msg
	 * tcp process task - process incoming packets for relaying or valve stuff
	 */

	uint8_t telemcounter = 0;
	uint8_t statecounter = 0;

	uint8_t num_limewires = 0;

	uint32_t onlineTick = HAL_GetTick();
	uint32_t heartTick = HAL_GetTick();
	uint32_t domeisoTick = HAL_GetTick();
	uint8_t startup_delay = 0;
	uint8_t gps_init = 0;
	/* Infinite loop */
	for(;;) {
		//size_t freemem = xPortGetFreeHeapSize();
		// Log and send error/status messages
		if(startup_delay > 4) {
			handle_logging();
			if(!gps_init) {
				gps_init = 1;
			    if(init_gps(&(sensors_h.gps_h), 500) != 0) {
			        log_message(FC_ERR_INIT_GPS, -1);
			    }
			}
		}

		// Send all valve states on connection with limewire
		if(HAL_GetTick() - onlineTick > 250) {
			onlineTick = HAL_GetTick();
			if(startup_delay < 5) {
				startup_delay++;
			}

			if(telemcounter == 0) {
				log_telemetry();
				telemcounter = 0; // 4hz
			}
			else {
				telemcounter--;
			}

			if(statecounter == 0) {
				log_valve_states();
				statecounter = 1; // 2hz
			}
			else {
				statecounter--;
			}

			refresh_log_timers();

			int num_limes = num_devices(LimeWire_d);
			if(num_limes >= 0) {
				if(num_limes > num_limewires) {
					// send
					uint64_t valvetime = get_rtc_time();
			  	  	if(xSemaphoreTake(Rocket_h.fcValve_access, 5) == pdPASS) {
			  	  		Valve_State_t vstates[3];
						for(int i = 0;i < 3;i++) {
							vstates[i] = Rocket_h.fcValveStates[i];
						}
			  	  		xSemaphoreGive(Rocket_h.fcValve_access);
						for(int i = 0;i < 3;i++) {
							Message statemsg = {0};
							statemsg.type = MSG_VALVE_STATE;
							statemsg.data.valve_state.timestamp = valvetime;
							statemsg.data.valve_state.valve_id = generate_valve_id(BOARD_FC, i);
							statemsg.data.valve_state.valve_state = vstates[i];
							send_msg_to_device(LimeWire_d, &statemsg, 5);
						}
			  	  	}
			  	  	if(xSemaphoreTake(Rocket_h.bb1Valve_access, 5) == pdPASS) {
			  	  		Valve_State_t vstates[7];
						for(int i = 0;i < 7;i++) {
							vstates[i] = Rocket_h.bb1ValveStates[i];
						}
			  	  		xSemaphoreGive(Rocket_h.bb1Valve_access);
						for(int i = 0;i < 7;i++) {
							Message statemsg = {0};
							statemsg.type = MSG_VALVE_STATE;
							statemsg.data.valve_state.timestamp = valvetime;
							statemsg.data.valve_state.valve_id = generate_valve_id(BOARD_BAY_1, i);
							statemsg.data.valve_state.valve_state = vstates[i];
							send_msg_to_device(LimeWire_d, &statemsg, 5);
						}
			  	  	}
			  	  	if(xSemaphoreTake(Rocket_h.bb2Valve_access, 5) == pdPASS) {
			  	  		Valve_State_t vstates[7];
						for(int i = 0;i < 7;i++) {
							vstates[i] = Rocket_h.bb2ValveStates[i];
						}
			  	  		xSemaphoreGive(Rocket_h.bb2Valve_access);
						for(int i = 0;i < 7;i++) {
							Message statemsg = {0};
							statemsg.type = MSG_VALVE_STATE;
							statemsg.data.valve_state.timestamp = valvetime;
							statemsg.data.valve_state.valve_id = generate_valve_id(BOARD_BAY_2, i);
							statemsg.data.valve_state.valve_state = vstates[i];
							send_msg_to_device(LimeWire_d, &statemsg, 5);
						}
			  	  	}
			  	  	if(xSemaphoreTake(Rocket_h.bb3Valve_access, 5) == pdPASS) {
			  	  		Valve_State_t vstates[7];
						for(int i = 0;i < 7;i++) {
							vstates[i] = Rocket_h.bb3ValveStates[i];
						}
			  	  		xSemaphoreGive(Rocket_h.bb3Valve_access);
						for(int i = 0;i < 7;i++) {
							Message statemsg = {0};
							statemsg.type = MSG_VALVE_STATE;
							statemsg.data.valve_state.timestamp = valvetime;
							statemsg.data.valve_state.valve_id = generate_valve_id(BOARD_BAY_3, i);
							statemsg.data.valve_state.valve_state = vstates[i];
							send_msg_to_device(LimeWire_d, &statemsg, 5);
						}
			  	  	}
				}
				num_limewires = num_limes;
			}
		}

		if(HAL_GetTick() - domeisoTick > 100) {
			domeisoTick = HAL_GetTick();

			int bb1_conn = num_devices(BayBoard1_d);
			if(bb1_conn >= 0) {
				if(bb1_conn > 0) {
					if(xSemaphoreTake(Rocket_h.fcState_access, 5) == pdPASS) {
						uint8_t cur_autos_state = Rocket_h.fcState.auto_sequence_state;
						xSemaphoreGive(Rocket_h.fcState_access);

						if(cur_autos_state > ST_DETECT_VALVES_OPEN && cur_autos_state < ST_DONE) {
							if(xSemaphoreTake(Rocket_h.bb1Valve_access, 5) == pdPASS) {
								Valve_State_t iso_state = Rocket_h.bb1ValveStates[loaded_config.fuel_iso_index];
								xSemaphoreGive(Rocket_h.bb1Valve_access);

								if(iso_state == Valve_Deenergized) {
									Message dome_force_msg = {0};
				    				dome_force_msg.type = MSG_VALVE_COMMAND;
				    				dome_force_msg.data.valve_command.valve_state = 0x01;
				    				dome_force_msg.data.valve_command.valve_id = generate_valve_id(BOARD_BAY_1, (Valve_Channel) loaded_config.fuel_iso_index);
				      				if(send_msg_to_device(BayBoard1_d, &dome_force_msg, 5) != 0) {
				      				// Server not up, target device not connected, or txbuffer is full
				      				}
								}
							}
						}
					}
				}
			}

			int bb2_conn = num_devices(BayBoard2_d);
			if(bb2_conn >= 0) {
				if(bb2_conn > 0) {
					if(xSemaphoreTake(Rocket_h.fcState_access, 5) == pdPASS) {
						uint8_t cur_autos_state = Rocket_h.fcState.auto_sequence_state;
						xSemaphoreGive(Rocket_h.fcState_access);

						if(cur_autos_state > ST_DETECT_VALVES_OPEN && cur_autos_state < ST_DONE) {
							if(xSemaphoreTake(Rocket_h.bb2Valve_access, 5) == pdPASS) {
								Valve_State_t iso_state = Rocket_h.bb2ValveStates[loaded_config.ox_iso_index];
								xSemaphoreGive(Rocket_h.bb2Valve_access);

								if(iso_state == Valve_Deenergized) {
									Message dome_force_msg = {0};
				    				dome_force_msg.type = MSG_VALVE_COMMAND;
				    				dome_force_msg.data.valve_command.valve_state = 0x01;
				    				dome_force_msg.data.valve_command.valve_id = generate_valve_id(BOARD_BAY_2, (Valve_Channel) loaded_config.ox_iso_index);
				      				if(send_msg_to_device(BayBoard2_d, &dome_force_msg, 5) != 0) {
				      				// Server not up, target device not connected, or txbuffer is full
				      				}
								}
							}
						}
					}
				}
			}
		}

		// Send heartbeat
		if(HAL_GetTick() - heartTick > 1000) {
			heartTick = HAL_GetTick();
			if(is_server_running() && num_devices(LimeWire_d) > 0) {
				Message heartbeat = {0};
				heartbeat.type = MSG_HEARTBEAT;
				send_msg_to_device(LimeWire_d, &heartbeat, 5);
			}
		}

  	  	if(xSemaphoreTake(sensors_h.gps_h.semaphore, 0) == pdTRUE) {
  	  		char nmea_sen[100];
  	  		memset(nmea_sen, 0, 100);
  	  		if(sensors_h.gps_h.active_rx_buffer == 2) {
  	  			strcpy(nmea_sen, (char*)sensors_h.gps_h.rx_buffer_1);
  	  			sensors_h.gps_h.rx_buffer_1_pos = 0;
  	  	    }
  	  	    else {
  	  	        strcpy(nmea_sen, (char*)sensors_h.gps_h.rx_buffer_2);
  	  	        sensors_h.gps_h.rx_buffer_2_pos = 0;
  	  	    }
  	  		enum minmea_sentence_id id = minmea_sentence_id(nmea_sen, false);
  	  		if(id == MINMEA_SENTENCE_GGA) {
  	  			gps_data gps_values = {0};
  	  			ParseStatus status = parse_gps_sentence(nmea_sen, &gps_values);
  	  			if(status == NORMAL) {
  	  				if(xSemaphoreTake(Rocket_h.fcState_access, 1) == pdPASS) {
  	  					Rocket_h.fcState.gps_lat = gps_values.latitude;
  	  					Rocket_h.fcState.gps_long = gps_values.longitude;
  	  					Rocket_h.fcState.gps_alt = gps_values.altitude;
  	  					Rocket_h.fcState.gps_sats = gps_values.sats_tracked;
  	  					xSemaphoreGive(Rocket_h.fcState_access);
  	  				}
  	  			}
  	  			else {
  	  				if(xSemaphoreTake(Rocket_h.fcState_access, 1) == pdPASS) {
  	  					Rocket_h.fcState.gps_lat = NAN;
  	  					Rocket_h.fcState.gps_long = NAN;
  	  					Rocket_h.fcState.gps_alt = NAN;
  	  					Rocket_h.fcState.gps_sats = NAN;
  	  					xSemaphoreGive(Rocket_h.fcState_access);
  	  				}
  	  			}
  	  	    }
  	  	}

		osDelay(5);
	}
  /* USER CODE END 5 */
}

 /* MPU Configuration */

void MPU_Config(void)
{
  MPU_Region_InitTypeDef MPU_InitStruct = {0};

  /* Disables the MPU */
  HAL_MPU_Disable();

  /** Initializes and configures the Region and the memory to be protected
  */
  MPU_InitStruct.Enable = MPU_REGION_ENABLE;
  MPU_InitStruct.Number = MPU_REGION_NUMBER0;
  MPU_InitStruct.BaseAddress = 0x0;
  MPU_InitStruct.Size = MPU_REGION_SIZE_4GB;
  MPU_InitStruct.SubRegionDisable = 0x87;
  MPU_InitStruct.TypeExtField = MPU_TEX_LEVEL0;
  MPU_InitStruct.AccessPermission = MPU_REGION_NO_ACCESS;
  MPU_InitStruct.DisableExec = MPU_INSTRUCTION_ACCESS_DISABLE;
  MPU_InitStruct.IsShareable = MPU_ACCESS_SHAREABLE;
  MPU_InitStruct.IsCacheable = MPU_ACCESS_NOT_CACHEABLE;
  MPU_InitStruct.IsBufferable = MPU_ACCESS_NOT_BUFFERABLE;

  HAL_MPU_ConfigRegion(&MPU_InitStruct);

  /** Initializes and configures the Region and the memory to be protected
  */
  MPU_InitStruct.Number = MPU_REGION_NUMBER1;
  MPU_InitStruct.BaseAddress = 0x30000200;
  MPU_InitStruct.Size = MPU_REGION_SIZE_32KB;
  MPU_InitStruct.SubRegionDisable = 0x0;
  MPU_InitStruct.TypeExtField = MPU_TEX_LEVEL1;
  MPU_InitStruct.AccessPermission = MPU_REGION_FULL_ACCESS;
  MPU_InitStruct.IsShareable = MPU_ACCESS_NOT_SHAREABLE;

  HAL_MPU_ConfigRegion(&MPU_InitStruct);

  /** Initializes and configures the Region and the memory to be protected
  */
  MPU_InitStruct.Number = MPU_REGION_NUMBER2;
  MPU_InitStruct.BaseAddress = 0x30000000;
  MPU_InitStruct.Size = MPU_REGION_SIZE_512B;
  MPU_InitStruct.TypeExtField = MPU_TEX_LEVEL0;
  MPU_InitStruct.IsShareable = MPU_ACCESS_SHAREABLE;
  MPU_InitStruct.IsBufferable = MPU_ACCESS_BUFFERABLE;

  HAL_MPU_ConfigRegion(&MPU_InitStruct);
  /* Enables the MPU */
  HAL_MPU_Enable(MPU_PRIVILEGED_DEFAULT);

}

void HAL_TIM_PeriodElapsedCallback(TIM_HandleTypeDef *htim)
{
  if (htim->Instance == TIM6)
  {
    HAL_IncTick();
  }
}

void Error_Handler(void)
{
  /* USER CODE BEGIN Error_Handler_Debug */
  /* User can add his own implementation to report the HAL error return state */
  //__disable_irq();
  while (1)
  {
  }
  /* USER CODE END Error_Handler_Debug */
}

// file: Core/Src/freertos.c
/* USER CODE BEGIN Header */
/**
  ******************************************************************************
  * File Name          : freertos.c
  * Description        : Code for freertos applications
  ******************************************************************************
  * @attention
  *
  * Copyright (c) 2025 STMicroelectronics.
  * All rights reserved.
  *
  * This software is licensed under terms that can be found in the LICENSE file
  * in the root directory of this software component.
  * If no LICENSE file comes with this software, it is provided AS-IS.
  *
  ******************************************************************************
  */
/* USER CODE END Header */

#include "FreeRTOS.h"
#include "task.h"
#include "main.h"

/* USER CODE BEGIN Variables */
extern TIM_HandleTypeDef htim14;
/* USER CODE END Variables */

/* Hook prototypes */
void configureTimerForRunTimeStats(void);
unsigned long getRunTimeCounterValue(void);
void vApplicationStackOverflowHook(xTaskHandle xTask, signed char *pcTaskName);

/* USER CODE BEGIN 1 */
/* Functions needed when configGENERATE_RUN_TIME_STATS is on */
__weak void configureTimerForRunTimeStats(void)
{
	HAL_TIM_Base_Start_IT(&htim14);
}
extern volatile unsigned long ulHighFrequencyTimerTicks;
__weak unsigned long getRunTimeCounterValue(void)
{
	return ulHighFrequencyTimerTicks;
}
/* USER CODE END 1 */

/* USER CODE BEGIN 4 */
void vApplicationStackOverflowHook(xTaskHandle xTask, signed char *pcTaskName)
{
	__BKPT(0);
   /* Run time stack overflow checking is performed if
   configCHECK_FOR_STACK_OVERFLOW is defined to 1 or 2. This hook function is
   called if a stack overflow is detected. */
}
/* USER CODE END 4 */
